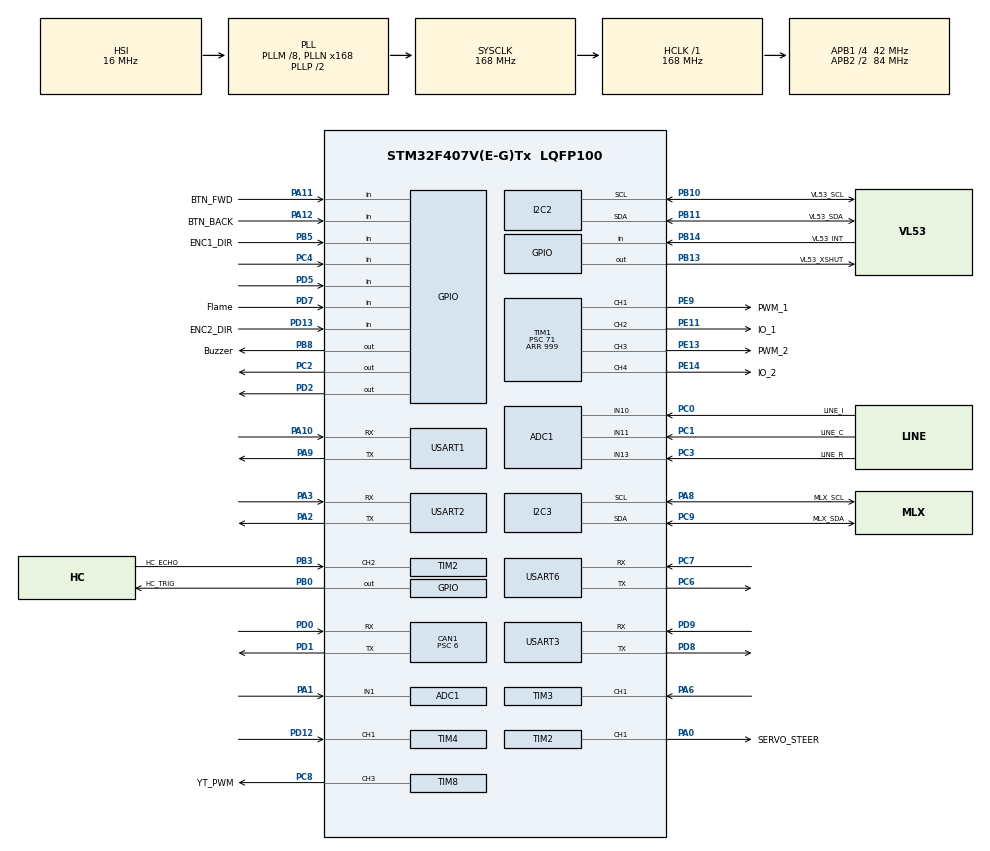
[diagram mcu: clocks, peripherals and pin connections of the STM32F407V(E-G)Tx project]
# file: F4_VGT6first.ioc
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ADC1.Channel-1\#ChannelRegularConversion=ADC_CHANNEL_1
ADC1.Channel-2\#ChannelRegularConversion=ADC_CHANNEL_10
ADC1.Channel-3\#ChannelRegularConversion=ADC_CHANNEL_11
ADC1.Channel-4\#ChannelRegularConversion=ADC_CHANNEL_13
ADC1.ClockPrescaler=ADC_CLOCK_SYNC_PCLK_DIV6
ADC1.ContinuousConvMode=ENABLE
ADC1.NbrOfConversion=4
ADC1.NbrOfConversionFlag=1
ADC1.Rank-1\#ChannelRegularConversion=1
ADC1.Rank-2\#ChannelRegularConversion=2
ADC1.Rank-3\#ChannelRegularConversion=3
ADC1.Rank-4\#ChannelRegularConversion=4
ADC1.SamplingTime-1\#ChannelRegularConversion=ADC_SAMPLETIME_84CYCLES
ADC1.SamplingTime-2\#ChannelRegularConversion=ADC_SAMPLETIME_480CYCLES
ADC1.SamplingTime-3\#ChannelRegularConversion=ADC_SAMPLETIME_480CYCLES
ADC1.SamplingTime-4\#ChannelRegularConversion=ADC_SAMPLETIME_480CYCLES
ADC1.ScanConvMode=ENABLE
ADC1.master=1
CAN1.ABOM=ENABLE
CAN1.BS1=CAN_BS1_11TQ
CAN1.BS2=CAN_BS2_2TQ
CAN1.CalculateBaudRate=500000
CAN1.CalculateTimeBit=2000
CAN1.CalculateTimeQuantum=142.85714285714286
CAN1.NART=ENABLE
CAN1.Prescaler=6
Dma.ADC1.1.Direction=DMA_PERIPH_TO_MEMORY
Dma.ADC1.1.FIFOMode=DMA_FIFOMODE_DISABLE
Dma.ADC1.1.Instance=DMA2_Stream0
Dma.ADC1.1.MemDataAlignment=DMA_MDATAALIGN_HALFWORD
Dma.ADC1.1.MemInc=DMA_MINC_ENABLE
Dma.ADC1.1.Mode=DMA_CIRCULAR
Dma.ADC1.1.PeriphDataAlignment=DMA_PDATAALIGN_HALFWORD
Dma.ADC1.1.PeriphInc=DMA_PINC_DISABLE
Dma.ADC1.1.Priority=DMA_PRIORITY_LOW
Dma.Request0=USART3_TX
Dma.Request1=ADC1
Dma.USART3_TX.0.Direction=DMA_MEMORY_TO_PERIPH
Dma.USART3_TX.0.FIFOMode=DMA_FIFOMODE_DISABLE
Dma.USART3_TX.0.Instance=DMA1_Stream3
Dma.USART3_TX.0.MemDataAlignment=DMA_MDATAALIGN_BYTE
Dma.USART3_TX.0.MemInc=DMA_MINC_ENABLE
Dma.USART3_TX.0.Mode=DMA_NORMAL
Dma.USART3_TX.0.PeriphDataAlignment=DMA_PDATAALIGN_BYTE
Dma.USART3_TX.0.PeriphInc=DMA_PINC_DISABLE
Dma.USART3_TX.0.Priority=DMA_PRIORITY_LOW
FREERTOS.Tasks01=defaultTask,24,128,StartDefaultTask,Default,NULL,Dynamic,NULL,NULL;MotionControlTa,48,256,StartMotionControlTask,Default,NULL,Dynamic,NULL,NULL;ScanTask,32,256,StartScanTask,Default,NULL,Dynamic,NULL,NULL;RangingTask,33,256,Ranging,Default,NULL,Dynamic,NULL,NULL;TelemetryTask,24,256,Telemetry,Default,NULL,Dynamic,NULL,NULL;EnvTask,16,512,Env,Default,NULL,Dynamic,NULL,NULL;ThermalTask,8,1024,Thermal,Default,NULL,Dynamic,NULL,NULL
FREERTOS.configTOTAL_HEAP_SIZE=32768
IWDG.Prescaler=IWDG_PRESCALER_64
IWDG.Reload=2499
Mcu.Family=STM32F4
Mcu.Name=STM32F407V(E-G)Tx
Mcu.Package=LQFP100
NVIC.CAN1_RX0_IRQn=true\:5\:0\:false\:false\:true\:true\:true\:true\:true
NVIC.CAN1_SCE_IRQn=true\:5\:0\:false\:false\:true\:true\:true\:true\:true
NVIC.DMA1_Stream3_IRQn=true\:5\:0\:false\:false\:true\:true\:false\:true\:true
NVIC.DMA2_Stream0_IRQn=true\:5\:0\:false\:false\:true\:true\:false\:true\:true
NVIC.PriorityGroup=NVIC_PRIORITYGROUP_4
NVIC.TIM6_DAC_IRQn=true\:15\:0\:false\:false\:true\:false\:false\:true\:true
NVIC.TimeBase=TIM6_DAC_IRQn
NVIC.TimeBaseIP=TIM6
NVIC.USART3_IRQn=true\:5\:0\:false\:false\:true\:true\:false\:true\:true
PA0-WKUP.GPIO_Label=SERVO_STEER
PA0-WKUP.Signal=S_TIM2_CH1_ETR
PA1.Signal=ADCx_IN1
PA10.Mode=Asynchronous
PA10.Signal=USART1_RX
PA11.GPIO_Label=BTN_FWD
PA11.GPIO_PuPd=GPIO_PULLDOWN
PA11.Signal=GPIO_Input
PA12.GPIO_Label=BTN_BACK
PA12.GPIO_PuPd=GPIO_PULLDOWN
PA12.Signal=GPIO_Input
PA13.Mode=Serial_Wire
PA13.Signal=SYS_JTMS-SWDIO
PA14.Mode=Serial_Wire
PA14.Signal=SYS_JTCK-SWCLK
PA2.Mode=Asynchronous
PA2.Signal=USART2_TX
PA3.Mode=Asynchronous
PA3.Signal=USART2_RX
PA6.Signal=S_TIM3_CH1
PA8.GPIO_Label=MLX_SCL
PA8.GPIO_Pu=GPIO_PULLUP
PA8.Mode=I2C
PA8.Signal=I2C3_SCL
PA9.Mode=Asynchronous
PA9.Signal=USART1_TX
PB0.GPIO_Label=HC_TRIG
PB0.Signal=GPIO_Output
PB10.GPIO_Label=VL53_SCL
PB10.GPIO_Pu=GPIO_PULLUP
PB10.Mode=I2C
PB10.Signal=I2C2_SCL
PB11.GPIO_Label=VL53_SDA
PB11.GPIO_Pu=GPIO_PULLUP
PB11.Mode=I2C
PB11.Signal=I2C2_SDA
PB13.GPIO_Label=VL53_XSHUT
PB13.Signal=GPIO_Output
PB14.GPIO_Label=VL53_INT
PB14.Signal=GPIO_Input
PB3.GPIO_Label=HC_ECHO
PB3.Signal=S_TIM2_CH2
PB5.GPIO_Label=ENC1_DIR
PB5.Signal=GPIO_Input
PB8.GPIO_Label=Buzzer
PB8.GPIO_OutputLevel=GPIO_PIN_SET
PB8.GPIO_PuPd=GPIO_NOPULL
PB8.GPIO_ModeDefaultOutputPP=GPIO_MODE_OUTPUT_OD
PB8.Signal=GPIO_Output
PC0.GPIO_Label=LINE_l
PC0.Signal=ADCx_IN10
PC1.GPIO_Label=LINE_C
PC1.Signal=ADCx_IN11
PC2.Signal=GPIO_Output
PC3.GPIO_Label=LINE_R
PC3.Signal=ADCx_IN13
PC4.Signal=GPIO_Input
PC6.Mode=Asynchronous
PC6.Signal=USART6_TX
PC7.Mode=Asynchronous
PC7.Signal=USART6_RX
PC8.GPIO_Label=YT_PWM
PC8.Signal=S_TIM8_CH3
PC9.GPIO_Label=MLX_SDA
PC9.GPIO_Pu=GPIO_PULLUP
PC9.Mode=I2C
PC9.Signal=I2C3_SDA
PD0.Mode=CAN_Activate
PD0.Signal=CAN1_RX
PD1.Mode=CAN_Activate
PD1.Signal=CAN1_TX
PD12.Signal=S_TIM4_CH1
PD13.GPIO_Label=ENC2_DIR
PD13.Signal=GPIO_Input
PD2.Signal=GPIO_Output
PD5.Signal=GPIO_Input
PD7.GPIO_Label=Flame
PD7.Signal=GPIO_Input
PD8.Mode=Asynchronous
PD8.Signal=USART3_TX
PD9.Mode=Asynchronous
PD9.Signal=USART3_RX
PE11.GPIO_Label=IO_1
PE11.GPIO_Speed=GPIO_SPEED_FREQ_VERY_HIGH
PE11.Signal=S_TIM1_CH2
PE13.GPIO_Label=PWM_2
PE13.GPIO_Speed=GPIO_SPEED_FREQ_VERY_HIGH
PE13.Signal=S_TIM1_CH3
PE14.GPIO_Label=IO_2
PE14.GPIO_Speed=GPIO_SPEED_FREQ_VERY_HIGH
PE14.Signal=S_TIM1_CH4
PE9.GPIO_Label=PWM_1
PE9.GPIO_Speed=GPIO_SPEED_FREQ_VERY_HIGH
PE9.Signal=S_TIM1_CH1
PH0-OSC_IN.Mode=HSE-External-Oscillator
PH0-OSC_IN.Signal=RCC_OSC_IN
PH1-OSC_OUT.Mode=HSE-External-Oscillator
PH1-OSC_OUT.Signal=RCC_OSC_OUT
ProjectManager.HeapSize=0x200
ProjectManager.StackSize=0x400
ProjectManager.TargetToolchain=CMake
RCC.48MHZClocksFreq_Value=84000000
RCC.AHBFreq_Value=168000000
RCC.APB1CLKDivider=RCC_HCLK_DIV4
RCC.APB1Freq_Value=42000000
RCC.APB1TimFreq_Value=84000000
RCC.APB2CLKDivider=RCC_HCLK_DIV2
RCC.APB2Freq_Value=84000000
RCC.APB2TimFreq_Value=168000000
RCC.CortexFreq_Value=168000000
RCC.HCLKFreq_Value=168000000
RCC.HSE_VALUE=25000000
RCC.HSI_VALUE=16000000
RCC.LSE_VALUE=32768
RCC.PLLM=8
RCC.PLLN=168
RCC.SYSCLKFreq_VALUE=168000000
RCC.SYSCLKSource=RCC_SYSCLKSOURCE_PLLCLK
RCC.VCOOutputFreq_Value=336000000
SH.ADCx_IN1.0=ADC1_IN1,IN1
SH.ADCx_IN10.0=ADC1_IN10,IN10
SH.ADCx_IN11.0=ADC1_IN11,IN11
SH.ADCx_IN13.0=ADC1_IN13,IN13
SH.S_TIM1_CH1.0=TIM1_CH1,PWM Generation1 CH1
SH.S_TIM1_CH2.0=TIM1_CH2,PWM Generation2 CH2
SH.S_TIM1_CH3.0=TIM1_CH3,PWM Generation3 CH3
SH.S_TIM1_CH4.0=TIM1_CH4,PWM Generation4 CH4
SH.S_TIM2_CH1_ETR.0=TIM2_CH1,PWM Generation1 CH1
SH.S_TIM2_CH2.0=TIM2_CH2,Input_Capture2_from_TI2
SH.S_TIM3_CH1.0=TIM3_CH1,TriggerSource_TI1FP1
SH.S_TIM4_CH1.0=TIM4_CH1,TriggerSource_TI1FP1
SH.S_TIM8_CH3.0=TIM8_CH3,PWM Generation3 CH3
TIM1.Channel-PWM\ Generation1\ CH1=TIM_CHANNEL_1
TIM1.Channel-PWM\ Generation2\ CH2=TIM_CHANNEL_2
TIM1.Channel-PWM\ Generation3\ CH3=TIM_CHANNEL_3
TIM1.Channel-PWM\ Generation4\ CH4=TIM_CHANNEL_4
TIM1.Period=999
TIM1.Prescaler=71
TIM2.Channel-Input_Capture2_from_TI2=TIM_CHANNEL_2
TIM2.Channel-PWM\ Generation1\ CH1=TIM_CHANNEL_1
TIM2.Period=19999
TIM2.Prescaler=83
TIM3.Slave_TriggerFilter=6
TIM3.TIM_MasterSlaveMode=TIM_MASTERSLAVEMODE_DISABLE
TIM4.Slave_TriggerFilter=6
TIM8.Channel-PWM\ Generation3\ CH3=TIM_CHANNEL_3
TIM8.Period=19999
TIM8.Prescaler=167
TIM8.Pulse-PWM\ Generation3\ CH3=1500
USART1.VirtualMode=VM_ASYNC
USART2.VirtualMode=VM_ASYNC
USART3.VirtualMode=VM_ASYNC
USART6.VirtualMode=VM_ASYNC
VP_FREERTOS_VS_CMSIS_V2.Mode=CMSIS_V2
VP_IWDG_VS_IWDG.Mode=IWDG_Activate
VP_SYS_VS_tim6.Mode=TIM6
VP_TIM3_VS_ControllerModeClock.Mode=Clock Mode
VP_TIM4_VS_ControllerModeClock.Mode=Clock Mode
board=custom

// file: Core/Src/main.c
/* USER CODE BEGIN Header */
/**
  ******************************************************************************
  * @file           : main.c
  * @brief          : Main program body
  ******************************************************************************
  * @attention
  *
  * Copyright (c) 2026 STMicroelectronics.
  * All rights reserved.
  *
  * This software is licensed under terms that can be found in the LICENSE file
  * in the root directory of this software component.
  * If no LICENSE file comes with this software, it is provided AS-IS.
  *
  ******************************************************************************
  */
/* USER CODE END Header */
#include "main.h"
#include "cmsis_os.h"
#include "adc.h"
#include "can.h"
#include "dma.h"
#include "i2c.h"
#include "iwdg.h"
#include "tim.h"
#include "usart.h"
#include "gpio.h"

/* USER CODE BEGIN Includes */
#include <stdio.h>
#include <string.h>
#include <stdarg.h>
#include "watchdog.h"
#include "motor.h"
#include "servo.h"
#include "servo2.h"
#include "encoder.h"
#include "hc.h"
#include "buzzer.h"
#include "mq2.h"
#include "flame.h"
#include "dht11.h"
#include "vl53l0x.h"
#include "linetrack.h"
#include "can_link.h"
/* USER CODE END Includes */

/* USER CODE BEGIN PV */
/* Retain the raw reset flags after RCC clears them, for UART/SWD diagnosis. */
volatile uint32_t g_boot_reset_flags = 0;
/* USER CODE END PV */

void SystemClock_Config(void);
void MX_FREERTOS_Init(void);

/* USER CODE BEGIN 0 */

/**
 * @brief  早期紧急错误输出（直接寄存器操作，不依赖 HAL/外设初始化状态）
 *         在任何阶段都能可靠输出到 USART6 (PC6 TX)。
 */
static void EarlyError_PutChar(char c)
{
    volatile uint32_t delay;
    for (delay = 0; delay < 72000; delay++) {
        if (USART6->SR & USART_SR_TXE) break;
    }
    USART6->DR = (uint8_t)c;
    if (c == '\n') {
        for (delay = 0; delay < 72000; delay++) {
            if (USART6->SR & USART_SR_TXE) break;
        }
        USART6->DR = '\r';
    }
}

static void EarlyError_Print(const char *s)
{
    if (!s) return;
    while (*s) EarlyError_PutChar(*s++);
}

static void EarlyError_Hex32(uint32_t val)
{
    static const char hex[] = "0123456789ABCDEF";
    EarlyError_PutChar('0'); EarlyError_PutChar('x');
    int started = 0;
    for (int i = 28; i >= 0; i -= 4) {
        uint8_t nib = (uint8_t)((val >> i) & 0x0F);
        if (nib || started || i == 0) {
            EarlyError_PutChar(hex[nib]);
            started = 1;
        }
    }
}

static void EarlyError_InitUART6(void)
{
    __HAL_RCC_USART6_CLK_ENABLE();
    __HAL_RCC_GPIOC_CLK_ENABLE();

    GPIO_InitTypeDef gpio = {
        .Pin       = GPIO_PIN_6,
        .Mode      = GPIO_MODE_AF_PP,
        .Pull      = GPIO_NOPULL,
        .Speed     = GPIO_SPEED_FREQ_VERY_HIGH,
        .Alternate = GPIO_AF8_USART6
    };
    HAL_GPIO_Init(GPIOC, &gpio);

    USART6->CR1 = 0;
    USART6->BRR = (uint16_t)((HAL_RCC_GetPCLK2Freq() + 57600) / 115200);
    USART6->CR3 = 0;
    USART6->CR2 = 0;
    USART6->CR1 = USART_CR1_UE | USART_CR1_TE;
}

/* USER CODE END 0 */

int main(void)
{

  /* MCU Configuration--------------------------------------------------------*/

  /* Reset of all peripherals, Initializes the Flash interface and the Systick. */
  HAL_Init();

  /* USER CODE BEGIN Init */
  /* Active-low PB8 must be silent before clock/peripheral initialization. */
  Buzzer_EarlySilence();
  g_boot_reset_flags = RCC->CSR;
  /* USER CODE END Init */

  /* Configure the system clock */
  SystemClock_Config();

  /* Initialize all configured peripherals */
  MX_GPIO_Init();
  MX_DMA_Init();
  MX_TIM1_Init();
  MX_TIM2_Init();
  MX_TIM3_Init();
  MX_TIM4_Init();
  MX_USART2_UART_Init();
  MX_USART3_UART_Init();
  MX_USART6_UART_Init();
  MX_I2C3_Init();
  MX_ADC1_Init();
  MX_I2C2_Init();
  MX_TIM8_Init();
  MX_USART1_UART_Init();
  MX_CAN1_Init();
  MX_IWDG_Init();
  /* USER CODE BEGIN 2 */

  /* 看门狗聚合喂狗：必须在 osKernelStart 之前清标记，否则任务尚未开始打点、
     WDG_Service 一上来就判超时，会在启动阶段直接触发复位。 */
  WDG_Init();

  /* ADC1 四通道 DMA 循环扫描（MQ2 + 3 路 TCRT 模拟量）。
     必须在 MX_DMA_Init() 与 MX_ADC1_Init() 都完成之后启动。 */
  ADC_StartDma();

  /* ---- 故障精确化：分离 Bus/Usage/MemManage 异常(不再一律升级为 HardFault)
     + 关闭默认写缓冲(DISDEFWBUF)让数据总线错误变“精确”(BFAR 给出确切地址)。
     配合 stm32f4xx_it.c 里的 Fault_Report, 崩溃时会从 USART6(PC6) 打印
     CFSR/BFAR/PC, 直接定位非法内存访问。 ---- */
  SCB->SHCSR |= (SCB_SHCSR_BUSFAULTENA_Msk | SCB_SHCSR_USGFAULTENA_Msk | SCB_SHCSR_MEMFAULTENA_Msk);
  SCnSCB->ACTLR |= SCnSCB_ACTLR_DISDEFWBUF_Msk;

  /* ---- 复位原因诊断：定位"启动不正常"根因（欠压/看门狗/软件/按键）----
     BORRST=电源欠压(供电不足) IWDGRST=任务卡死被看门狗复位
     SFTRST=软件复位 PINRST=按键/NRST(正常手动复位) PORRST=正常上电 */
  {
    const char *cause = "UNKNOWN";
    if      (__HAL_RCC_GET_FLAG(RCC_FLAG_IWDGRST)) cause = "IWDG(看门狗复位，需核对任务/故障计数)";
    else if (__HAL_RCC_GET_FLAG(RCC_FLAG_WWDGRST)) cause = "WWDG(窗口看门狗)";
    else if (__HAL_RCC_GET_FLAG(RCC_FLAG_SFTRST))  cause = "SOFT(软件复位)";
    else if (__HAL_RCC_GET_FLAG(RCC_FLAG_PORRST))  cause = "POR/PDR(上电/掉电复位)";
    else if (__HAL_RCC_GET_FLAG(RCC_FLAG_BORRST))  cause = "BOR(电源复位标志，需核对供电)";
    else if (__HAL_RCC_GET_FLAG(RCC_FLAG_PINRST))  cause = "PIN(按键/NRST)";
    LOG("[RESET] flags=0x%08lX cause=%s", (unsigned long)g_boot_reset_flags, cause);
    __HAL_RCC_CLEAR_RESET_FLAGS();
  }

  /* ---- 电机：设载波频率 → 启动 TIM1 四通道 PWM + 使能驱动 ---- */
  /* Motor_Init 把 PWM 载波从 2.33kHz 提到 21kHz（消除啸叫，见 motor.h）。
     必须在 HAL_TIM_PWM_Start 之前设好预分频。 */
  Motor_Init();
  HAL_TIM_PWM_Start(&htim1, TIM_CHANNEL_1);   // Motor1 EN (PE9)
  HAL_TIM_PWM_Start(&htim1, TIM_CHANNEL_2);   // Motor1 PH (PE11)
  HAL_TIM_PWM_Start(&htim1, TIM_CHANNEL_3);   // Motor2 EN (PE13)
  HAL_TIM_PWM_Start(&htim1, TIM_CHANNEL_4);   // Motor2 PH (PE14)
  DRV8701_Enable();                            // 使能电机驱动（外部开关）
  Motor1_Set(0);
  Motor2_Set(0);
  LOG("[BRINGUP] Motors PWM started, DRV8701 enabled, stopped");

  /* ---- 转向舵机 (TIM2_CH1 PA0)，回中 ---- */
  Servo_Init();
  Servo_SetAngle(0);       // 中位
  LOG("[BRINGUP] Steering servo ready, centered (PA0)");

  /* ---- OLED 已移除（2026-07-08 硬件取消，CubeMX 已删 I2C1） ---- */

  /* ---- 编码器 (TIM3 ETR=PA6 / TIM4 ETR=PD12) ---- */
  Encoder_Init();
  LOG("[BRINGUP] Encoders ready (TIM3 PA6 / TIM4 PD12)");

  /* ---- HC-SR04 超声波 (PB0 TRIG / PB3 TIM2_CH2 ECHO) ---- */
  HC_Init();
  LOG("[BRINGUP] HC-SR04 ready (TRIG=PB0, ECHO=TIM2_CH2 PB3)");

  /* ---- 环境/安全传感器 ---- */
  Buzzer_Init();                     // PB8 有源蜂鸣器
  HAL_GPIO_WritePin(ALARM_OUT_GPIO_Port, ALARM_OUT_Pin, GPIO_PIN_RESET);  // PD2 报警联动初始关
  MQ2_Init();                        // PA1(AO)/PC4(DO) 烟雾气体
  Flame_Init();                      // PD7 火焰
  DHT11_Init();                      // PD5 温湿度
  LineTrack_Init();                  // PC0/PC1/PC3 循迹 TCRT×3（GPIO 由 CubeMX 配）
  LOG("[BRINGUP] Env sensors init (MQ2/Flame/DHT11/Buzzer/LineTrack)");
  /* VL53L0X：先总线诊断，再最多 3 次重试初始化（冷启动/上电时序偶发抖动）。
     失败也不阻塞——RangingTask 会在运行时每 2s 自恢复重试(见 Ranging())。 */
  uint8_t vl_id = 0;
  uint8_t vl_probe = VL53_BusProbe(&vl_id);
  int vl = -99;
  for (int attempt = 0; attempt < 3; attempt++) {
    vl = VL53_Init();
    if (vl == 0) break;
    HAL_Delay(20);
  }
  if (vl == 0) {
    LOG("[BRINGUP] VL53L0X ready (I2C2, cont.)  probe=%u id=0x%02X", vl_probe, vl_id);
  } else if (vl_probe == 0) {
    LOG("[BRINGUP] VL53L0X FAIL: 总线无ACK(id=0x%02X) -> 查 PB10=SCL/PB11=SDA/PB13=XSHUT/3.3V/上拉。运行时会自恢复", vl_id);
  } else {
    LOG("[BRINGUP] VL53L0X FAIL: init=%d probe=%u id=0x%02X(应0xEE) -> 芯片应答但初始化未过。运行时会自恢复", vl, vl_probe, vl_id);
  }
  /* VL53 失败 → 扫 I2C2 总线一锤定音：
     0 器件应答 = 总线级问题(上拉缺失/未供电/SDA-SCL接反/未共地/XSHUT压低)；
     有器件 = 芯片在线(0x29=VL53默认)，问题在地址/初始化。 */
  if (vl != 0) {
    int i2c_found = 0;
    for (uint8_t a = 0x08; a <= 0x77; a++) {
      if (HAL_I2C_IsDeviceReady(&hi2c2, (uint16_t)(a << 1), 1, 3) == HAL_OK) {
        LOG("[I2C2] device ACK @0x%02X (7-bit)", a);
        i2c_found++;
      }
    }
    if (i2c_found == 0)
      LOG("[I2C2] 总线全哑: 0 器件应答 -> 上拉缺失 / 未供3.3V / SDA-SCL接反 / 未共地");
    else
      LOG("[I2C2] 共 %d 器件应答 (VL53 默认 7-bit 0x29)", i2c_found);
  }

  /* ---- 云台舵机 Servo2 (PB1, TIM2 中断硬件定时 PWM)，回中 ---- */
  Servo2_Init();
  Servo2_SetPulse(SERVO2_MID);  // 云台回中（非阻塞，脉冲由 TIM2 中断持续生成）
  LOG("[BRINGUP] Pan servo (Servo2) ready, centered (PB1)");

  /* ---- CAN 链路（500kbps，CANopen Node 1，见实施方案 §3）----
     CubeMX 只建外设(MX_CAN1_Init)；过滤器/启动/中断通知须手写，缺了收不到任何帧。
     只放行 0x201 命令 / 0x301 巡检避障 / 0x601 SDO；上行遥测走 0x181/0x281/0x381/0x701。
     USART3 保留为回退链路（LINK_USE_CAN 开关，见 freertos.c）。 */
  CANLink_Init();
#if CAN_LOOPBACK_TEST
  LOG("========================================================");
  LOG("  !!! CAN SILENT-LOOPBACK SELF-TEST MODE (P1) !!!");
  LOG("  TX internally looped to RX; CANTX pin held recessive.");
  LOG("  NOT on the real bus -- PCAN will see NOTHING. Expected.");
  LOG("  PASS = [CAN] tx+ rxoth+ err=0 boff=0 TEC=0 REC=0 LEC=NoErr");
  LOG("  -> then set CAN_LOOPBACK_TEST=0 in can_link.h and reflash!");
  LOG("========================================================");
#else
  LOG("[BRINGUP] CAN1 up @500kbps (RX:0x201/0x301/0x601  TX:0x181/0x281/0x381/0x701)");
#endif

  /* 固件版本横幅：烧录后看这行即可确认跑的是不是最新固件（含各修复） */
  LOG("[FW] F4 v1.25.5: active-low PB8 open-drain silence; corrected line sensor L/R");

  LOG("[BRINGUP] All peripherals OK -> starting FreeRTOS scheduler");
  LOG("[INFO] Startup holds servos centered; bench self-checks are disabled by default");
  LOG("[INFO]   PA11 = Forward, PA12 = Backward (active-low)");

  /* USER CODE END 2 */

  /* Init scheduler */
  osKernelInitialize();  /* Call init function for freertos objects (in cmsis_os2.c) */
  MX_FREERTOS_Init();

  /* Start scheduler */
  osKernelStart();

  /* We should never get here as control is now taken by the scheduler */

  /* Infinite loop */
  while (1)
  {

  }
}

void SystemClock_Config(void)
{
  RCC_OscInitTypeDef RCC_OscInitStruct = {0};
  RCC_ClkInitTypeDef RCC_ClkInitStruct = {0};

  /** Configure the main internal regulator output voltage
  */
  __HAL_RCC_PWR_CLK_ENABLE();
  __HAL_PWR_VOLTAGESCALING_CONFIG(PWR_REGULATOR_VOLTAGE_SCALE1);

  /** Initializes the RCC Oscillators according to the specified parameters
  * in the RCC_OscInitTypeDef structure.
  */
  RCC_OscInitStruct.OscillatorType = RCC_OSCILLATORTYPE_HSI|RCC_OSCILLATORTYPE_LSI;
  RCC_OscInitStruct.HSIState = RCC_HSI_ON;
  RCC_OscInitStruct.HSICalibrationValue = RCC_HSICALIBRATION_DEFAULT;
  RCC_OscInitStruct.LSIState = RCC_LSI_ON;
  RCC_OscInitStruct.PLL.PLLState = RCC_PLL_ON;
  RCC_OscInitStruct.PLL.PLLSource = RCC_PLLSOURCE_HSI;
  RCC_OscInitStruct.PLL.PLLM = 8;
  RCC_OscInitStruct.PLL.PLLN = 168;
  RCC_OscInitStruct.PLL.PLLP = RCC_PLLP_DIV2;
  RCC_OscInitStruct.PLL.PLLQ = 4;
  if (HAL_RCC_OscConfig(&RCC_OscInitStruct) != HAL_OK)
  {
    Error_Handler();
  }

  /** Initializes the CPU, AHB and APB buses clocks
  */
  RCC_ClkInitStruct.ClockType = RCC_CLOCKTYPE_HCLK|RCC_CLOCKTYPE_SYSCLK
                              |RCC_CLOCKTYPE_PCLK1|RCC_CLOCKTYPE_PCLK2;
  RCC_ClkInitStruct.SYSCLKSource = RCC_SYSCLKSOURCE_PLLCLK;
  RCC_ClkInitStruct.AHBCLKDivider = RCC_SYSCLK_DIV1;
  RCC_ClkInitStruct.APB1CLKDivider = RCC_HCLK_DIV4;
  RCC_ClkInitStruct.APB2CLKDivider = RCC_HCLK_DIV2;

  if (HAL_RCC_ClockConfig(&RCC_ClkInitStruct, FLASH_LATENCY_5) != HAL_OK)
  {
    Error_Handler();
  }
}

/* USER CODE BEGIN 4 */

/**
 * @brief  printf() 重定向到 USART6 (PC6 TX)
 *         这样 printf() 输出可以从调试串口看到。
 */
int __io_putchar(int ch)
{
    /* 如果在 USART6 初始化完成前调用，则不输出 */
    if (huart6.Instance == USART6 && (USART6->CR1 & USART_CR1_UE))
    {
        /* 轮询等待 TXE，然后写入 DR */
        while (!(USART6->SR & USART_SR_TXE));
        USART6->DR = (uint8_t)(ch & 0xFF);
    }
    return ch;
}

/**
 * @brief  printf 风格日志输出到 USART6 (PC6 TX)，供 main.h 的 LOG() 宏调用。
 *         FreeRTOS 任务通过 LOG() → UART_Log() 输出调试信息到独立调试串口，
 *         不占用 USART3（蓝牙遥控数据帧通道）。
 */
void UART_Log(const char *format, ...)
{
    char buffer[128];
    va_list args;
    va_start(args, format);
    int len = vsnprintf(buffer, sizeof(buffer), format, args);
    va_end(args);
    /* ★关键：vsnprintf 返回的是“未截断时的完整长度”，可能 > sizeof(buffer)。
       必须夹取到实际写入缓冲区的字节数，否则 HAL_UART_Transmit 会越界读取
       buffer 之后的栈内存——当日志行超过 128B 时会一路读到 RAM 顶 0x20020000
       触发精确总线错误(PRECISERR)。夹到 sizeof-1(截断后有效字符数)。 */
    if (len > (int)sizeof(buffer) - 1) len = (int)sizeof(buffer) - 1;
    if (len > 0)
    {
        /* 有限超时(20ms)：即使 USART6/PC6 调试口异常也不会把启动/任务冻死。
           128B @115200 约 11ms，20ms 留足余量；超时则丢弃本行、继续运行。 */
        HAL_UART_Transmit(&huart6, (uint8_t *)buffer, (uint16_t)len, 20);
    }
}

/**
 * @brief  FreeRTOS configASSERT 调用此函数输出诊断信息
 */
void vAssertCalled(const char *file, int line)
{
    /* 直接写 USART6 寄存器（不依赖 HAL/OS） */
    if (USART6->CR1 & USART_CR1_UE)
    {
        const char *p;
        p = "\r\n!!! RTOS ASSERT: ";
        while (*p) { while(!(USART6->SR & USART_SR_TXE)); USART6->DR = *p++; }
        while (*file) { while(!(USART6->SR & USART_SR_TXE)); USART6->DR = *file++; }
        /* 冒号 + 行号 */
        char tmp[16];
        int n = snprintf(tmp, sizeof(tmp), ":%d !!!\r\n", line);
        for (int i = 0; i < n && i < 16; i++) {
            while(!(USART6->SR & USART_SR_TXE));
            USART6->DR = (uint8_t)tmp[i];
        }
    }
}

/* USER CODE END 4 */

void HAL_TIM_PeriodElapsedCallback(TIM_HandleTypeDef *htim)
{
  if (htim->Instance == TIM6)
  {
    HAL_IncTick();
  }
}

void Error_Handler(void)
{
  /* USER CODE BEGIN Error_Handler_Debug */

  /* 第一步：使能 USART6 并输出（总是尝试，即使此时外设尚未初始化） */
  EarlyError_InitUART6();
  EarlyError_Print("\r\n");
  EarlyError_Print("!!!!!!!!!!!!!!!!!!!!!!!!!!!\r\n");
  EarlyError_Print("  ERROR HANDLER TRIGGERED\r\n");
  EarlyError_Print("  CR1="); EarlyError_Hex32(USART6->CR1);
  EarlyError_Print("  SR=");  EarlyError_Hex32(USART6->SR);
  EarlyError_Print("\r\n  USART3: CR1="); EarlyError_Hex32(USART3->CR1);
  EarlyError_Print("  SR=");  EarlyError_Hex32(USART3->SR);
  EarlyError_Print("\r\n!!!!!!!!!!!!!!!!!!!!!!!!!!!\r\n");

  __disable_irq();
  while (1)
  {
  }
  /* USER CODE END Error_Handler_Debug */
}
#ifdef USE_FULL_ASSERT
/**
  * @brief  Reports the name of the source file and the source line number
  *         where the assert_param error has occurred.
  * @param  file: pointer to the source file name
  * @param  line: assert_param error line source number
  * @retval None
  */
void assert_failed(uint8_t *file, uint32_t line)
{
  /* USER CODE BEGIN 6 */
  EarlyError_InitUART6();
  EarlyError_Print("\r\n!!! ASSERT FAILED: ");
  EarlyError_Print((const char*)file);
  EarlyError_PutChar(':');
  /* 手动输出行号 */
  uint32_t n = line;
  char rev[12]; int ri = 0;
  do { rev[ri++] = '0' + (n % 10); n /= 10; } while (n);
  while (ri > 0) EarlyError_PutChar(rev[--ri]);
  EarlyError_Print(" !!!\r\n");
  __disable_irq();
  while (1);
  /* USER CODE END 6 */
}
#endif /* USE_FULL_ASSERT */

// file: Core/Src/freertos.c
/* USER CODE BEGIN Header */
/**
  ******************************************************************************
  * File Name          : freertos.c
  * Description        : Code for freertos applications
  ******************************************************************************
  * @attention
  *
  * Copyright (c) 2026 STMicroelectronics.
  * All rights reserved.
  *
  * This software is licensed under terms that can be found in the LICENSE file
  * in the root directory of this software component.
  * If no LICENSE file comes with this software, it is provided AS-IS.
  *
  ******************************************************************************
  */
/* USER CODE END Header */

#include "FreeRTOS.h"
#include "task.h"
#include "main.h"
#include "cmsis_os.h"

/* USER CODE BEGIN Includes */
#include "servo.h"
#include "servo2.h"
#include "motor.h"
#include "motion_control.h"
#include "encoder.h"
#include "hc.h"
#include "protocol.h"
#include "stdio.h"
#include "string.h"
#include "tim.h"
#include "usart.h"
#include "bt_debug.h"
#include "boot_trace.h"
#include "thermal.h"
#include "buzzer.h"
#include "mq2.h"
#include "flame.h"
#include "dht11.h"
#include "vl53l0x.h"
#include "linetrack.h"
#include "patrol.h"
#include "runtime_control.h"
#include "watchdog.h"
#include "i2c_recover.h"
#include "pid.h"
#include "can_link.h"
/* USER CODE END Includes */

/* USER CODE BEGIN PTD */

/* ============================================================================
 *  任务分层（2026-07-08 重构，对应《深度优化报告》方案A + CubeMX 任务表）：
 *    MotionControlTa (Realtime,   17ms) 运动闭环：遥控解析/差速/PID/测试激励
 *    RangingTask     (AboveNorm1,  1ms) 测距采集：HC 状态机推进 + VL53 非阻塞读
 *    ScanTask        (AboveNormal)      云台默认居中保持；全行程自检仅限台架
 *    TelemetryTask   (Normal,     20ms) 上报专职：7B 遥测 + 扩展帧 + PID 遥测
 *    EnvTask         (BelowNormal,100ms)慢速环境：MQ2/火焰/DHT11/蜂鸣 + 0x5C
 *    ThermalTask     (Low,        200ms)热成像原始帧转发（USART1 专线）
 *  原则：采集/决策/上报分离；阻塞大户(DHT11/热成像TX)下沉低优先级；
 *        Encoder_Update 仅 MotionControlTask 调用（修双任务竞态）；
 *        OLED 已移除（硬件取消，2026-07-08）。
 * ==========================================================================*/

/* 平滑过渡速度档位 */
#define RAMP_REMOTE_STEP    SERVO_RAMP_FAST_STEP   // 遥控模式：步长上限，比例步长自动减速收尾
#define RAMP_SWITCH_STEP    8                       // 模式切换：中速步长上限

/* ===== 遥控避障锁（2026-07-23）=========================================
 *  遥控时操作不当容易撞前方障碍。加一道硬锁：前方过近立即停止前进，
 *  且【不会因为障碍移开就自动放行】，必须操作者二次确认才解锁，
 *  避免"贴着障碍物继续推摇杆"这种最危险的情形。
 *
 *  触发：前方有效距离 <= OBS_LOCK_ON_MM（8cm）
 *  解锁：障碍已退到 OBS_LOCK_OFF_MM（12cm，迟滞防抖）之外，
 *        且操作者连续给出 OBS_UNLOCK_NEED 次【新的前进意图】。
 *        "新的前进意图" = speed 从 <=0 跳变到 >0 的上升沿 —— 之所以用边沿
 *        而不是数帧，是因为龙芯 30Hz 持续下发命令帧（兼心跳），
 *        按帧数算 2 帧只要 66ms，锁形同虚设；用边沿则要求操作者
 *        真的松手再推两次，才是有意义的"二次确认"。
 *  锁定期间：前进(speed>0)一律置 0；后退(speed<0)放行，便于倒车脱困。 */
#define OBS_LOCK_ON_MM       80U    /* 8cm：进入锁定 */
#define OBS_LOCK_OFF_MM     120U    /* 12cm：迟滞解除阈值，防止在阈值附近反复抖动 */
#define OBS_UNLOCK_NEED       2U    /* 需要的前进意图边沿次数 */
#define OBS_UNLOCK_WINDOW_MS 5000U  /* 两次意图的最大间隔，超时清零重新计数 */

/* ★ 2026-07-23 实测修正：触发锁必须连续确认，且优先信任激光。
 *   现象：行进中超声波读数剧烈跳变（85cm→17cm→9cm→85cm），同期 VL53 稳定 867mm。
 *   根因：HC-SR04 锥角宽(±15°)，车一动就打到地面/侧物产生假回波，叠加电机 EMI。
 *   原实现取 min(VL53,HC) 且【单次读数即触发】，正好被这些毛刺打中 ——
 *   一跳到 9cm 就锁死前进，操作者推两次解锁后又被下一个毛刺锁上，
 *   表现为行进中反复顿挫，也就是用户反馈的"卡顿"。
 *   现策略：
 *     1) VL53 有效时【以 VL53 为准】—— 窄视场、抗 EMI、毫米级精度；
 *        仅当 VL53 超量程(前方 1.2m 内无目标)时才回退到超声波。
 *     2) 无论用哪个源，都要连续 OBS_CONFIRM_N 次判近才真正锁定，单次毛刺不算数。 */
#define OBS_CONFIRM_N         3U    /* 连续确认次数（17ms/次 → 约 51ms 才锁） */

/* 云台开机建图扫描步长(us/10ms循环)：全行程 2000us / 8 ≈ 2.5s 单程 */
#define SWEEP2_STEP         8

/* USER CODE END PTD */

/* USER CODE BEGIN PD */

/* Heartbeat deadlines use elapsed RTOS milliseconds, not loop counts. */
#define HB_ACTIVE_MAX 85U
#define HB_HOLD_MAX 510U

/* Full-travel boot tests are bench-only: do not load both servos at power-on. */
#ifndef BOOT_SERVO_SELF_TEST_ENABLED
#define BOOT_SERVO_SELF_TEST_ENABLED 0
#endif
#ifndef BOOT_PAN_SCAN_ENABLED
#define BOOT_PAN_SCAN_ENABLED 0
#endif

#ifndef THERMAL_TASK_ENABLED
#define THERMAL_TASK_ENABLED 1     /* MLX90640 原始帧转发（USART1 专线） */
#endif

/* ★ CAN 链路开关（实施方案 §3.6.6）：1=上行遥测/心跳同时走 CAN（与 USART3 并行，
   便于 A/B 对比与 candump 验证）；0=仅 USART3。命令 RX 两条链路始终都收，
   谁连着谁生效（见 can_link.c 的 0x201 分发与 usart.c 的 ISR）。 */
#ifndef LINK_USE_CAN
#define LINK_USE_CAN 1
#endif

/* CPS controller parameters are defined in motion_control.c. */
#define PID_TUNING_ENABLED   0

/* USER CODE END PD */

/* USER CODE BEGIN Variables */

/* USART3 发送互斥锁：TelemetryTask / EnvTask 共用同一 TX，
   用带优先级继承的互斥锁串行化，避免帧交错损坏。 */
osMutexId_t g_usart3_mtx = NULL;
static const osMutexAttr_t usart3_mtx_attr = {
  .name = "usart3Tx",
  .attr_bits = osMutexPrioInherit,
};

/* 加锁发送一帧到 USART3（互斥锁未建成时退化为直接发送） */
static void USART3_SendFrameSync(const uint8_t *f, uint8_t len)
{
  if (g_usart3_mtx) osMutexAcquire(g_usart3_mtx, osWaitForever);
  USART3_SendFrame(f, len);
  if (g_usart3_mtx) osMutexRelease(g_usart3_mtx);
}

/* USART6 debug port (COM26 on the bench): accept the same binary control/PID
   frames as USART3 so PID can be tuned directly through the local USB-serial
   adapter, without Loongson/LongLook in the loop. */
#define DBG_RX_STATE_IDLE 0U
#define DBG_RX_STATE_RECV 1U
static uint8_t dbg_rx_state = DBG_RX_STATE_IDLE;
static uint8_t dbg_rx_frame[FRAME_PIDPARAM_LENGTH];
static uint8_t dbg_rx_idx = 0;
static uint8_t dbg_rx_expect = FRAME_LENGTH;

static void DebugUart_ProcessRxByte(uint8_t byte)
{
    static uint32_t lastByteMs=0;
    uint32_t now=HAL_GetTick();
    if(now-lastByteMs>50U) { dbg_rx_state=0; dbg_rx_idx=0; }
    lastByteMs=now;
  switch (dbg_rx_state)
  {
  case DBG_RX_STATE_IDLE:
    if (byte == FRAME_HEADER)
    {
      dbg_rx_frame[0] = byte;
      dbg_rx_idx = 1;
      dbg_rx_expect = FRAME_LENGTH;
      dbg_rx_state = DBG_RX_STATE_RECV;
    }
    break;

  case DBG_RX_STATE_RECV:
    if (dbg_rx_idx == 1U)
    {
      if      (byte == 0x63U) dbg_rx_expect = 12U;
      else if (byte == FRAME_PIDPARAM_MARKER) dbg_rx_expect = FRAME_PIDPARAM_LENGTH;
      else if (byte == FRAME_PIDTEST_MARKER)  dbg_rx_expect = FRAME_PIDTEST_LENGTH;
      else                                    dbg_rx_expect = FRAME_LENGTH;
    }
/* A payload byte 0xAA is legal (e.g. speed=170); only inter-byte timeout resynchronizes. */
    dbg_rx_frame[dbg_rx_idx++] = byte;
    if (dbg_rx_idx >= dbg_rx_expect)
    {
      uint8_t raw[FRAME_PIDPARAM_LENGTH];
      for (uint8_t i = 0; i < dbg_rx_expect; ++i) raw[i] = dbg_rx_frame[i];

      if (dbg_rx_expect == 12U) { Runtime_UartRequest(raw); }
      else if (dbg_rx_expect == FRAME_PIDPARAM_LENGTH)
      {
#if PID_TUNING_ENABLED
        if (Protocol_CalculateChecksum(raw, FRAME_PIDPARAM_LENGTH - 1U) == raw[FRAME_PIDPARAM_LENGTH - 1U] &&
            Protocol_UnpackPidParam(raw, &g_pid_param_rx))
        {
          g_pid_param_ready = 1;
          g_rx_pid_frame_cnt++;
          LOG("[DDBG] PID param frame accepted via USART6");
        }
        else g_rx_crc_err++;
#endif
      }
      else if (dbg_rx_expect == FRAME_PIDTEST_LENGTH)
      {
#if PID_TUNING_ENABLED
        if (Protocol_CalculateChecksum(raw, FRAME_PIDTEST_LENGTH - 1U) == raw[FRAME_PIDTEST_LENGTH - 1U] &&
            Protocol_UnpackPidTest(raw, &g_pid_test_rx))
        {
          g_pid_test_ready = 1;
          g_rx_pid_frame_cnt++;
          LOG("[DDBG] PID test frame accepted via USART6");
        }
        else g_rx_crc_err++;
#endif
      }
      else if ((raw[5] & TELEMETRY_FLAG) == 0U)
      {
        ControlData tmp;
        if (Protocol_UnpackCommandFrame(raw, &tmp))
        {
          g_remote_data = tmp;
          g_remote_ready = 1;
          g_rx_frame_cnt++;
          LOG("[DDBG] cmd via USART6 spd=%d steer=%d mode=%u", tmp.speed, tmp.steering, tmp.mode);
        }
        else g_rx_crc_err++;
      }

      dbg_rx_state = DBG_RX_STATE_IDLE;
      dbg_rx_idx = 0;
    }
    break;
  }
}

static void DebugUart_PollRx(void)
{
  while (__HAL_UART_GET_FLAG(&huart6, UART_FLAG_RXNE))
  {
    DebugUart_ProcessRxByte((uint8_t)(huart6.Instance->DR & 0xFFU));
  }
  if (__HAL_UART_GET_FLAG(&huart6, UART_FLAG_ORE))
  {
    __HAL_UART_CLEAR_OREFLAG(&huart6);
    dbg_rx_state = DBG_RX_STATE_IDLE;
    dbg_rx_idx = 0;
  }
}

/* 链路激活标志：由 MotionControlTask 维护（1=SBC/手柄已连接）。
   Telemetry/Env/Thermal 据此决定是否上报，避免链路空闲时占满 USART3。 */
volatile uint8_t g_remote_active = 0;

/* ---- RangingTask 发布的激光测距（EnvTask/运动决策消费，32 位读写在 M4 上原子） ---- */
volatile uint16_t g_vl53_mm      = VL53_OUT_OF_RANGE;
volatile uint32_t g_vl53_ok_cnt  = 0;    /* 有效样本计数（诊断链路活性） */
volatile uint8_t  g_line_bits    = 0;    /* 循迹位域(L/C/R/junction/lost)，RangingTask 发布 */
volatile uint8_t  g_obs_lock     = 0;    /* 遥控避障锁状态，MotionControlTask 发布，EnvTask 上报 */

/* ---- 巡检事件/状态（MotionControlTask 产生 → TelemetryTask 经 CAN 0x481 上报）---- */
volatile uint8_t  g_patrol_state     = 0;   /* PatrolStateT */
volatile uint8_t  g_patrol_event     = 0;   /* PatrolEventT，待上报 */
volatile uint8_t  g_patrol_point_seq = 0;   /* 路口计数 */
volatile uint8_t  g_patrol_evt_ready = 0;   /* 1=有新事件待发 */

/* ---- MotionControlTask 发布的运动快照（TelemetryTask 消费） ---- */
volatile int16_t g_mot_speed      = 0;   /* 当前命令速度 */
volatile int16_t g_mot_steer_tele = 0;   /* 舵机回读转向(-1000~1000) */
volatile uint8_t g_mot_mode       = MODE_MANUAL;

/* Read-only controller snapshot: Motor1=left/ENC2, Motor2=right/ENC1; CPS. */
volatile uint8_t g_pt_flags = 0;   /* bit0=closed-loop, bit2=motion fault */
volatile int16_t g_pt_targL = 0, g_pt_measL = 0, g_pt_outL = 0;
volatile int16_t g_pt_targR = 0, g_pt_measR = 0, g_pt_outR = 0;
volatile uint8_t g_motion_fault = 0;
volatile uint32_t g_motion_dt_us = 17000;

/* USER CODE END Variables */
/* Definitions for defaultTask */
osThreadId_t defaultTaskHandle;
const osThreadAttr_t defaultTask_attributes = {
  .name = "defaultTask",
  .stack_size = 128 * 4,
  .priority = (osPriority_t) osPriorityNormal,
};
/* Definitions for MotionControlTa */
osThreadId_t MotionControlTaHandle;
const osThreadAttr_t MotionControlTa_attributes = {
  .name = "MotionControlTa",
  .stack_size = 384 * 4,
  .priority = (osPriority_t) osPriorityRealtime,
};
/* Definitions for ScanTask */
osThreadId_t ScanTaskHandle;
const osThreadAttr_t ScanTask_attributes = {
  .name = "ScanTask",
  .stack_size = 256 * 4,
  .priority = (osPriority_t) osPriorityAboveNormal,
};
/* Definitions for RangingTask */
osThreadId_t RangingTaskHandle;
const osThreadAttr_t RangingTask_attributes = {
  .name = "RangingTask",
  .stack_size = 256 * 4,
  .priority = (osPriority_t) osPriorityAboveNormal1,
};
/* Definitions for TelemetryTask */
osThreadId_t TelemetryTaskHandle;
const osThreadAttr_t TelemetryTask_attributes = {
  .name = "TelemetryTask",
  .stack_size = 256 * 4,
  .priority = (osPriority_t) osPriorityNormal,
};
/* Definitions for EnvTask */
osThreadId_t EnvTaskHandle;
const osThreadAttr_t EnvTask_attributes = {
  .name = "EnvTask",
  .stack_size = 512 * 4,
  .priority = (osPriority_t) osPriorityBelowNormal,
};
/* Definitions for ThermalTask */
osThreadId_t ThermalTaskHandle;
const osThreadAttr_t ThermalTask_attributes = {
  .name = "ThermalTask",
  .stack_size = 1024 * 4,
  .priority = (osPriority_t) osPriorityLow,
};

void StartDefaultTask(void *argument);
void StartMotionControlTask(void *argument);
void StartScanTask(void *argument);
void Ranging(void *argument);
void Telemetry(void *argument);
void Env(void *argument);
void Thermal(void *argument);

void MX_FREERTOS_Init(void); /* (MISRA C 2004 rule 8.1) */

void MX_FREERTOS_Init(void) {

  /* USER CODE BEGIN RTOS_MUTEX */
  g_usart3_mtx = osMutexNew(&usart3_mtx_attr);
  /* USER CODE END RTOS_MUTEX */

  /* Create the thread(s) */
  /* creation of defaultTask */
  defaultTaskHandle = osThreadNew(StartDefaultTask, NULL, &defaultTask_attributes);

  /* creation of MotionControlTa */
  MotionControlTaHandle = osThreadNew(StartMotionControlTask, NULL, &MotionControlTa_attributes);

  /* creation of ScanTask */
  ScanTaskHandle = osThreadNew(StartScanTask, NULL, &ScanTask_attributes);

  /* creation of RangingTask */
  RangingTaskHandle = osThreadNew(Ranging, NULL, &RangingTask_attributes);

  /* creation of TelemetryTask */
  TelemetryTaskHandle = osThreadNew(Telemetry, NULL, &TelemetryTask_attributes);

  /* creation of EnvTask */
  EnvTaskHandle = osThreadNew(Env, NULL, &EnvTask_attributes);

  /* creation of ThermalTask */
  ThermalTaskHandle = osThreadNew(Thermal, NULL, &ThermalTask_attributes);

  /* USER CODE BEGIN RTOS_THREADS */
  /* 旧 EnvSensorTask/ThermalTask(USER CODE 版) 已迁入 CubeMX 任务表的
     EnvTask/ThermalTask（上方生成区创建），此处不再重复创建。 */
  /* USER CODE END RTOS_THREADS */

}

void StartDefaultTask(void *argument)
{
  /* USER CODE BEGIN StartDefaultTask */
  /* 独立蜂鸣器快速节拍：环境任务含 DHT11 阻塞读，不能承担报警节奏。 */
  for(;;)
  {
    Buzzer_Tick(20U);
    osDelay(20U);
  }
  /* USER CODE END StartDefaultTask */
}

void StartMotionControlTask(void *argument)
{
  /* USER CODE BEGIN StartMotionControlTask */
  DUART_Trace("MotionControlTask started (Realtime priority)");

  // 启动 USART3 接收中断
  MX_USART3_StartRx();
  BTDbg_Init();
  LOG("[TASK] MotionControlTask started (Realtime). Steering self-check begins.");

  #define MOTOR_TEST_SPEED  500

  int16_t current_speed = 0;
  uint8_t current_mode = MODE_MANUAL;

  // 心跳超时跟踪
  uint32_t s_remote_tick = 0;
  uint8_t  remote_active  = 0;           // 0=纯本地模式, 1=遥控已激活

  // 差速转向：保存从遥控帧中解析的原始转向值 (-1000~+1000)
  int16_t s_raw_steering  = 0;
  int16_t s_last_left_spd  = 0;
  int16_t s_last_right_spd = 0;

  // 遥控避障锁状态（见文件头 OBS_LOCK_* 宏说明）
  uint8_t  s_obs_lock       = 0;   /* 1=锁定中，前进被强制归零 */
  uint8_t  s_obs_near_cnt   = 0;   /* 连续判近次数，达 OBS_CONFIRM_N 才锁（抗毛刺） */
  uint8_t  s_obs_unlock_cnt = 0;   /* 已累计的前进意图边沿次数 */
  uint32_t s_obs_last_intent_ms = 0; /* 最近一次前进意图时刻，用于超时清零 */
  int16_t  s_obs_prev_cmd_spd = 0; /* 上一帧遥控速度，用于检测 <=0 -> >0 上升沿 */

  // 舵机自检状态机：0=INIT,1=→LEFT,2=WAIT_L,3=→RIGHT,4=WAIT_R,5=→CENTER,6=DONE
  uint8_t  sc_state = BOOT_SERVO_SELF_TEST_ENABLED ? 0U : 6U;
  uint8_t  sc_wait  = 0;

  MotionControl motion; Motion_Init(&motion);
  uint32_t sampleCycles = 0, controlDeadline = osKernelGetTickCount();
  uint8_t previousMode = MODE_MANUAL;
  int8_t   last_btn_cmd = 0;

  for(;;)
  {
    // ===== 0. 看门狗：本任务打存活点 + 聚合校验后喂狗（唯一喂狗点） =====
    /* 改造前是无条件 IWDG->KR=0xAAAA，只能发现整块 MCU 死掉；
       现由 WDG_Service 校验【所有】受监护任务都在截止期内打过点才喂狗，
       任一任务卡死或数据异常累计超限即停止喂狗，约 5s 后 IWDG 复位。 */
    WDG_Kick(WDG_TASK_MOTION);
    WDG_Service();

    // ===== 显式启用的台架自检阶段（默认关闭；期间不动驱动电机） =====
    if (sc_state < 6)
    {
      uint8_t arrived = (Servo_RampTick() == 0);
      switch (sc_state)
      {
      case 0:
        Servo_SetSmoothAngle(SERVO_ANGLE_MAX, SERVO_RAMP_FAST_STEP);
        LOG("[SELF-CHECK 1/3] Steering -> LEFT  +%d deg", SERVO_ANGLE_MAX);
        sc_state = 1;
        break;
      case 1:
        if (arrived) { sc_wait = 8; sc_state = 2; }
        break;
      case 2:
        if (--sc_wait == 0) {
          Servo_SetSmoothAngle(SERVO_ANGLE_MIN, SERVO_RAMP_FAST_STEP);
          LOG("[SELF-CHECK 2/3] Steering -> RIGHT %d deg", SERVO_ANGLE_MIN);
          sc_state = 3;
        }
        break;
      case 3:
        if (arrived) { sc_wait = 8; sc_state = 4; }
        break;
      case 4:
        if (--sc_wait == 0) {
          Servo_SetSmoothAngle(0, SERVO_RAMP_FAST_STEP);
          LOG("[SELF-CHECK 3/3] Steering -> CENTER (reset)");
          sc_state = 5;
        }
        break;
      case 5:
        if (arrived) {
          sc_state = 6;
          LOG("[SELF-CHECK] DONE. Steering centered, pulse=%u us", Servo_GetCurrentPulse());
          LOG("[READY] Buttons: PA11=Forward PA12=Backward. Ctrl RX on USART3.");
        }
        break;
      }
      osDelay(17);
      continue;
    }

    // ===== 正常控制阶段 ============================================

    Servo_RampTick();
    DebugUart_PollRx();
    USART3_PollRx();
    USART3_EnsureRxActive();
    uint8_t operator_update = 0;
    int16_t operator_speed = 0;

    // ===== 1. 遥控数据消费（优先级高于本地按键） =====
    if (g_remote_ready)
    {
      taskENTER_CRITICAL();
      ControlData remote = g_remote_data;
      g_remote_ready = 0;
      taskEXIT_CRITICAL();

      s_remote_tick = osKernelGetTickCount();
      remote_active = 1;

      current_speed = remote.speed;
      operator_speed = remote.speed;
      operator_update = 1;
      current_mode  = remote.mode;
      s_raw_steering = remote.steering;

      if (current_speed > CONTROL_SPEED_MAX_LEVEL)  current_speed = CONTROL_SPEED_MAX_LEVEL;
      if (current_speed < -CONTROL_SPEED_MAX_LEVEL) current_speed = -CONTROL_SPEED_MAX_LEVEL;

      int16_t target_angle = (int16_t)(-(int32_t)remote.steering * 90 / 1000);
      if (target_angle < SERVO_ANGLE_MIN) target_angle = SERVO_ANGLE_MIN;
      if (target_angle > SERVO_ANGLE_MAX) target_angle = SERVO_ANGLE_MAX;
      Servo_SetSmoothAngle(target_angle, RAMP_REMOTE_STEP);
    }
    else if (!remote_active)
    {
      // 本地按键（PA11 前进 / PA12 后退，内部下拉，按下=1）
      uint8_t btn_forward  = HAL_GPIO_ReadPin(BTN_FWD_GPIO_Port, BTN_FWD_Pin);
      uint8_t btn_backward = HAL_GPIO_ReadPin(BTN_BACK_GPIO_Port, BTN_BACK_Pin);

      int8_t btn_cmd;
      if      (btn_forward == 1 && btn_backward == 0) { current_speed =  Runtime_Speed(); btn_cmd = 1; }
      else if (btn_backward == 1 && btn_forward == 0) { current_speed = -(int16_t)Runtime_Speed(); btn_cmd = -1; }
      else                                            { current_speed = 0; btn_cmd = 0; }
      operator_speed = current_speed;
      operator_update = 1;

      if (btn_cmd != last_btn_cmd)
      {
        last_btn_cmd = btn_cmd;
        if (btn_cmd == 1)       LOG("[BTN] FWD -> speed=%d", (int)Runtime_Speed());
        else if (btn_cmd == -1) LOG("[BTN] BACK -> speed=%d", -(int)Runtime_Speed());
        else                    LOG("[BTN] released -> STOP");
      }
    }

    // ===== 1.3 遥控避障锁（仅遥控模式；循迹模式由 patrol.c 自己的停障逻辑负责）=====
    /* 距离融合：VL53(mm) 与超声波(cm) 取【更近的有效值】——两者视场互补，
       任一发现近障都应停车，宁可保守。无效值(0/超量程)不参与比较。 */
    if (current_mode == MODE_MANUAL)
    {
      uint16_t vl53   = g_vl53_mm;
      uint32_t hc_cm  = HC_GetDistance_cm();
      uint16_t near_mm = 0xFFFFU;                     /* 0xFFFF = 前方净空 */
      /* ★ 优先信任激光：VL53 在量程内就只看它，不让超声波的假回波参与判定。
         只有 VL53 超量程（前方 1.2m 内确实没东西）时才回退到超声波兜底。 */
      if (vl53 != VL53_OUT_OF_RANGE && vl53 > 0U)
        near_mm = vl53;
      else if (hc_cm > 0U)
        near_mm = (uint16_t)(hc_cm * 10U);

      uint32_t now_ms = HAL_GetTick();

      /* (1) 进入锁定：需连续 OBS_CONFIRM_N 次判近，单次毛刺不触发 */
      if (near_mm <= OBS_LOCK_ON_MM)
      {
        if (s_obs_near_cnt < 0xFFU) s_obs_near_cnt++;
        if (!s_obs_lock && s_obs_near_cnt >= OBS_CONFIRM_N)
        {
          s_obs_lock = 1;
          s_obs_unlock_cnt = 0;
          /* LOG 走 115200 裸串口，只用 ASCII —— 中文会乱码成 "3?????????" */
          LOG("[OBS] LOCK on: front=%umm (<=%umm, confirmed x%u) -> forward blocked",
              near_mm, (unsigned)OBS_LOCK_ON_MM, (unsigned)s_obs_near_cnt);
        }
        if (s_obs_lock) s_obs_unlock_cnt = 0;         /* 障碍还在，任何确认都作废 */
      }
      else
      {
        s_obs_near_cnt = 0;                           /* 一旦读到不近就清确认计数 */
      }

      /* (2) 前进意图边沿检测：speed 从 <=0 跳到 >0 记一次 */
      if (s_obs_lock)
      {
        if (operator_update && s_obs_prev_cmd_spd <= 0 && operator_speed > 0)
        {
          /* 超时窗口：两次确认间隔过久则重新计数，避免"很久以前推过一次"被算进来 */
          if (s_obs_last_intent_ms != 0U &&
              (now_ms - s_obs_last_intent_ms) > OBS_UNLOCK_WINDOW_MS)
            s_obs_unlock_cnt = 0;
          s_obs_last_intent_ms = now_ms;

          /* 只有障碍已退到迟滞阈值之外，确认才计数——贴着障碍推摇杆不算数 */
          if (near_mm > OBS_LOCK_OFF_MM)
          {
            s_obs_unlock_cnt++;
            LOG("[OBS] unlock intent %u/%u (front=%umm)",
                s_obs_unlock_cnt, (unsigned)OBS_UNLOCK_NEED, near_mm);
            if (s_obs_unlock_cnt >= OBS_UNLOCK_NEED)
            {
              s_obs_lock = 0;
              s_obs_unlock_cnt = 0;
              LOG("[OBS] LOCK released by operator confirm");
            }
          }
          else
          {
            /* 限流：贴着障碍持续推摇杆时这条会每 17ms 打一次，几秒就刷屏几十条，
               把 [DIST]/[PIDTRK] 等真正有用的信息冲掉。每 500ms 最多打一条。 */
            static uint32_t s_lastRejLogMs = 0;
            if ((now_ms - s_lastRejLogMs) > 500U)
            {
              s_lastRejLogMs = now_ms;
              LOG("[OBS] unlock rejected: obstacle still near (front=%umm, need >%umm)",
                  near_mm, (unsigned)OBS_LOCK_OFF_MM);
            }
          }
        }
      }
      /* A safety-generated zero is not an operator release. Only received
         commands / physical buttons may create another unlock edge. */
      if (operator_update) s_obs_prev_cmd_spd = operator_speed;

      /* (3) 锁定生效：前进归零，后退放行（倒车脱困） */
      if (s_obs_lock && current_speed > 0)
        current_speed = 0;
    }
    else
    {
      /* 切出遥控模式：清锁，避免残留状态影响下次进遥控 */
      s_obs_lock = 0;
      s_obs_near_cnt = 0;
      s_obs_unlock_cnt = 0;
      s_obs_prev_cmd_spd = 0;
    }
    g_obs_lock = s_obs_lock;      /* 发布给 EnvTask 打 ENV_FLAG_OBS_LOCK 上报 */

    // ===== 1.4 龙芯下发的巡检命令（CAN 0x301 sub=0x01/0x02）=====
    if (g_patrol_cmd_ready)
    {
      uint8_t c = g_patrol_cmd_rx; g_patrol_cmd_ready = 0;
      switch (c) {
        case 0: Patrol_Stop();   LOG("[PATROL] cmd STOP");   break;
        case 1: Patrol_Start();  LOG("[PATROL] cmd START");  break;
        case 2: Patrol_Pause();  LOG("[PATROL] cmd PAUSE");  break;
        case 3: Patrol_Resume(); LOG("[PATROL] cmd RESUME"); break;
        default: break;
      }
    }
    if (g_patrol_act_ready)
    {
      uint8_t act = g_patrol_act_action; g_patrol_act_ready = 0;
      Patrol_ResumeFromPoint(act);       /* 到点放行：龙芯认完点给出下一步动作 */
      LOG("[PATROL] act point=%u action=%u", g_patrol_act_point, act);
    }

    // ===== 1.5 循迹模式：本地循线快环覆盖遥控值 =====
    /* 三模式（protocol.h）：
     *   MODE_REMOTE(0)      —— 不介入，用上面遥控消费得到的 speed/steering
     *   MODE_LINE_ONLY(1)   —— F4 本地 TCRT 循线
     *   MODE_LINE_VISION(3) —— 同样本地循线（保证断网可跑），龙芯视觉只作叠加约束
     * ★ 循线快环完全在 F4 本地闭合：即使 CAN/龙芯抖动或断开，巡线照常，
     *   不会因为链路问题冲出线外。龙芯只负责启停、认点、到点放行。 */
    if (current_mode == MODE_LINE_ONLY || current_mode == MODE_LINE_VISION)
    {
      if (previousMode != current_mode && !Patrol_IsActive()) Patrol_Start();     /* 切入循迹模式即自动启动 */

      int16_t p_spd = 0, p_str = 0;
      /* 前向距离：超声波(已中值滤波)，HC_NO_TARGET_CM 表示空旷 */
      uint16_t front = (uint16_t)HC_GetDistance_cm();
      if (front == 0u) front = HC_NO_TARGET_CM;

      PatrolEventT ev = Patrol_Update(&p_spd, &p_str, front);

      /* 台架联调开关(PATROL_BENCH_STEER_ONLY)：1=驱动轮不转、只动舵机。
         供电已拆分后默认恢复实车循迹；若需要悬空只验证转向，可临时改回 1。 */
#ifndef PATROL_BENCH_STEER_ONLY
#define PATROL_BENCH_STEER_ONLY 0
#endif
#if PATROL_BENCH_STEER_ONLY
      p_spd = 0;
#endif

      current_speed  = p_spd;
      s_raw_steering = p_str;

      /* 交给既有舵机管线（阿克曼：转向只由舵机执行） */
      int16_t ta = (int16_t)(-(int32_t)p_str * 90 / 1000);
      if (ta < SERVO_ANGLE_MIN) ta = SERVO_ANGLE_MIN;
      if (ta > SERVO_ANGLE_MAX) ta = SERVO_ANGLE_MAX;
      Servo_SetSmoothAngle(ta, RAMP_REMOTE_STEP);

      /* 事件上报龙芯（CAN 0x481 sub=0x01），由 TelemetryTask 取走 */
      if (ev != PATROL_EV_NONE) {
        g_patrol_event     = (uint8_t)ev;
        g_patrol_point_seq = Patrol_GetPointSeq();
        g_patrol_evt_ready = 1;
        LOG("[PATROL] event=%u seq=%u state=%u", ev, g_patrol_point_seq, Patrol_GetState());
      }
      g_patrol_state = (uint8_t)Patrol_GetState();
    }
    else if (Patrol_IsActive())
    {
      Patrol_Stop();                              /* 切出循迹模式即停止 */
      g_patrol_state = (uint8_t)Patrol_GetState();
      LOG("[PATROL] stopped (mode=%u)", current_mode);
    }

    previousMode = current_mode;
    // ===== 2. 阿克曼驱动速度合成 =====
    /* ★ 2026-07-21 阿克曼修正（实施方案 §2.6 / §3.1）：
     *   旧实现按【差速车】用 steering 合成 turn_factor，让左右轮一加一减。
     *   但本车是【阿克曼底盘】——转向完全由前轮舵机(PA0/TIM2_CH1)执行，
     *   驱动轮只负责推进。再叠加差速等于把同一个转向意图【施加两次】，
     *   会造成：转弯半径比舵机指令更小、内外轮与转向角不匹配而拖胎、
     *   直行时任何微小 steering 都让两轮速度不等而跑偏。
     *
     *   正解：两个驱动轮给【同一目标速度】，转向只由舵机负责。
     *   （严格阿克曼下内外轮应有微小速差 v_in/v_out = 1 ∓ (W/2)·tanδ/L，
     *     但本车轮距 W 小、巡检转弯半径大，该差值 <2%，且后轮多为差速器/
     *     独立驱动可自行吸收；引入它反而需要精确的 δ 反馈，得不偿失。
     *     故统一给同速——这也是绝大多数阿克曼小车的标准做法。） */
    #define CLAMP_SPD(v)  do { if ((v) > CONTROL_SPEED_MAX_LEVEL) (v) = CONTROL_SPEED_MAX_LEVEL; \
                                if ((v) < -CONTROL_SPEED_MAX_LEVEL) (v) = -CONTROL_SPEED_MAX_LEVEL; } while(0)

    int16_t left_speed  = current_speed;
    int16_t right_speed = current_speed;

    const uint8_t autonomous_mode =
        (current_mode == MODE_LINE_ONLY || current_mode == MODE_LINE_VISION) ? 1U : 0U;

    if (autonomous_mode)
    {
      /* 自主巡检快环属于 F4 本地控制，不受上位机遥控帧年龄影响。
         CAN 短暂断流时仍持续循线；模式/急停命令恢复后会立即接管。 */
      CLAMP_SPD(left_speed);
      CLAMP_SPD(right_speed);
      s_last_left_spd  = left_speed;
      s_last_right_spd = right_speed;
    }
    else if (!remote_active)
    {
      s_last_left_spd = current_speed;
      s_last_right_spd = current_speed;
    }
    else if ((uint32_t)(osKernelGetTickCount()-s_remote_tick) <= HB_ACTIVE_MAX)
    {
      /* 阿克曼：两驱动轮同速，不做差速合成（s_raw_steering 只驱动舵机，见第 1 段） */
      CLAMP_SPD(left_speed);
      CLAMP_SPD(right_speed);
      s_last_left_spd  = left_speed;
      s_last_right_spd = right_speed;
    }
    else if ((uint32_t)(osKernelGetTickCount()-s_remote_tick) <= HB_HOLD_MAX)
    {
      left_speed  = s_last_left_spd;
      right_speed = s_last_right_spd;
    }
    else
    {
      left_speed  = 0;
      right_speed = 0;
      current_speed = 0;
      remote_active = 0;
      s_last_left_spd  = 0;
      s_last_right_spd = 0;
      s_raw_steering   = 0;
      Servo_SetSmoothAngle(SERVO_ANGLE_MID, RAMP_SWITCH_STEP);

    }

    /* Every motion source shares this limit, including heartbeat-held commands.
       PID duty is still free to reach the limited encoder target under load. */
    left_speed = Control_Clamp(left_speed, Runtime_Speed());
    right_speed = Control_Clamp(right_speed, Runtime_Speed());
    /* DWT runs during IRQ masking and measures the actual encoder interval.
       Calibration no longer assumes every loop physically lasts exactly 17ms. */
    uint32_t cycles = DWT->CYCCNT;
    uint32_t elapsedUs = sampleCycles ? (uint32_t)(cycles-sampleCycles)/(SystemCoreClock/1000000U) : 17000U;
    sampleCycles = cycles;
    Encoder_UpdateElapsed(elapsedUs);
    int16_t outputs[2];
    /* 2026-10-09 single-wheel test: Motor1 drives ENC2; Motor2 drives ENC1. */
    Motion_Update(&motion,left_speed,s_raw_steering,Encoder2_GetDelta(),Encoder1_GetDelta(),
                  elapsedUs,Encoder_IsSampleValid(),outputs);
    /* High gear -> sharp turn: slow first, then progressively admit the
       requested angle. Servo_RampTick above consumes this bounded target
       on the next cycle; every motion source uses the same envelope. */
    int16_t safeSteering=Motion_LimitSteering(&motion,s_raw_steering);
    int16_t safeAngle=-(int16_t)((int32_t)safeSteering*90/1000);
    if(safeAngle<SERVO_ANGLE_MIN) safeAngle=SERVO_ANGLE_MIN;
    if(safeAngle>SERVO_ANGLE_MAX) safeAngle=SERVO_ANGLE_MAX;
    Servo_SetSmoothAngle(safeAngle,RAMP_REMOTE_STEP);
    Motor1_Set(outputs[0]);Motor2_Set(outputs[1]);
    g_pt_flags = (uint8_t)(1U | (motion.fault ? 4U : 0U));
    g_motion_fault = motion.fault;
    g_motion_dt_us = elapsedUs;
    g_pt_targL = g_pt_targR = (int16_t)motion.command;
    g_pt_measL = Motion_TelemetryCps(motion.measured[0]);g_pt_measR = Motion_TelemetryCps(motion.measured[1]);
    g_pt_outL = outputs[0];g_pt_outR = outputs[1];
    g_mot_speed = motion.fault ? 0 : (int16_t)motion.command;
    g_mot_steer_tele = -(int16_t)((int32_t)Servo_GetCurrentAngle() * 1000 / 90);
    g_mot_mode       = current_mode;

    g_remote_active = remote_active;

    controlDeadline += 17U;
    if ((int32_t)(controlDeadline-osKernelGetTickCount()) > 0) osDelayUntil(controlDeadline);
    else { controlDeadline=osKernelGetTickCount(); osDelay(1); }
  }
  /* USER CODE END StartMotionControlTask */
}

void StartScanTask(void *argument)
{
  /* USER CODE BEGIN StartScanTask */
  /* 云台状态：
       ① 默认上电居中静止，HC 前视，不自动跑极限位置；
       ② BOOT_PAN_SCAN_ENABLED 仅供台架显式启用全行程自检；
       ③ ON_DEMAND：激光近障触发的按需扫描——随运动状态机接入（后续里程碑）。
     HC/编码器/OLED 均已移出本任务（HC→RangingTask，编码器→MotionControl，OLED 移除）。 */
  LOG("[TASK] ScanTask: %s", BOOT_PAN_SCAN_ENABLED ?
      "bench boot sweep enabled" : "center hold; automatic boot sweep disabled");

  uint16_t pulse = BOOT_PAN_SCAN_ENABLED ? SERVO2_MIN : SERVO2_MID;
  int8_t   phase = BOOT_PAN_SCAN_ENABLED ? 0 : 2; /* 0=去MAX 1=回MIN 2=居中 */
  Servo2_SetPulse(pulse);
  osDelay(300);                 /* 等云台到位 */

  for(;;)
  {
    WDG_Kick(WDG_TASK_SCAN);   /* 只打存活点，实际喂狗由 MotionControlTask 聚合判定 */

    if (phase == 0)
    {
      pulse += SWEEP2_STEP;
      if (pulse >= SERVO2_MAX) { pulse = SERVO2_MAX; phase = 1; }
      Servo2_SetPulse(pulse);
      osDelay(10);
    }
    else if (phase == 1)
    {
      pulse -= SWEEP2_STEP;
      if (pulse <= SERVO2_MID) { pulse = SERVO2_MID; phase = 2;
        LOG("[SCAN] boot sweep done -> center hold (dist=%lucm)", HC_GetDistance_cm()); }
      Servo2_SetPulse(pulse);
      osDelay(10);
    }
    else
    {
      /* 居中静止：低频保持（后续 ON_DEMAND 扫描在此接收触发） */
      Servo2_SetPulse(SERVO2_MID);
      osDelay(100);
    }
  }
  /* USER CODE END StartScanTask */
}

void Ranging(void *argument)
{
  /* USER CODE BEGIN Ranging */
  /* 高频测距采集（AboveNormal1，1ms 粒度）——《深度优化报告》M1/M3：
       · HC-SR04 状态机 1ms 推进（旧版在 ScanTask 10ms 粒度 + OLED 阻塞，触发
         时序被拖慢；现在 TRIG 10us/50us 相位仅耗 1~2ms，测距可达物理极限）；
       · VL53L0X 每 10ms 非阻塞读一次（连续测距模式，仅查就绪位，绝不忙等）。
     全程无打印、无 OLED、无阻塞大户——它只做采集和发布。 */
  LOG("[TASK] RangingTask: HC @1ms tick + VL53 try-read @10ms");

  uint32_t cyc = 0;
  uint32_t hc_last_ms = 0;   /* 上次发起 HC 测量的时刻，用于 ≥60ms 间隔限速 */
  uint32_t vl53_retry_ms = HAL_GetTick();
  /* VL53 超量程去抖：连续 VL53_MISS_N 次才判"真的没目标"，期间保持最后有效值 */
  #define VL53_MISS_N   5U   /* 5 次 × 10ms ≈ 50ms */
  uint8_t  s_vl53_miss = 0;
  for(;;)
  {
    WDG_Kick(WDG_TASK_RANGING);
    /* HC 状态机推进（触发时序 + 超时判定；边沿在 TIM2 中断捕获） */
    HC_ProcessTick();
    /* ★ HC-SR04 测量间隔 ≥60ms(HC_MEAS_INTERVAL_MS)：数据手册要求相邻测量≥60ms，
       否则上一次 ping 余响未散就再发，近距目标(<50cm)"回波时有时无"(pulse 在 0 与
       真值间跳)——这正是近距 [DIST] 间歇 0 的根因。原 back-to-back(~150-300Hz)过快。 */
    if (!HC_IsMeasuring() && (HAL_GetTick() - hc_last_ms >= HC_MEAS_INTERVAL_MS))
    {
      HC_StartMeasurement();
      hc_last_ms = HAL_GetTick();
    }

    /* 循迹 TCRT×3：内部固定5ms中值/迟滞采样，多任务读取不会加快去抖。 */
    g_line_bits = LineTrack_PackBits(LineTrack_Read());
    Runtime_SetLineReady(LineTrack_IsCalibrated());

    /* VL53 非阻塞取样（~30ms 测量预算，10ms 轮询足够取走每个样本） */
    if ((++cyc % 10U) == 0U)
    {
      uint16_t mm;
      if (VL53_TryReadRange_mm(&mm))
      {
        if (mm != VL53_OUT_OF_RANGE)
        {
          /* 有效读数：立即发布并清失效计数 */
          g_vl53_mm = mm;
          s_vl53_miss = 0;
          g_vl53_ok_cnt++;
        }
        else
        {
          /* ★ 2026-07-23 超量程去抖：
             VL53L0X 在目标接近量程上限(~1.2m)或反射率低时，会【间歇】返回超量程
             哨兵 8190。实测约 1/3 的采样是 8190，而 g_vl53_ok_cnt 同期稳定增长
             （每秒 20~25 次有效读数）—— 说明传感器工作正常，只是边缘条件下不稳。
             旧实现把 8190 直接覆盖 g_vl53_mm，导致上位机与小屏看到的是
             "880mm / 无数据" 来回跳，也就是"拿不到稳定数据"。
             现改为：连续 VL53_MISS_N 次超量程才真的对外发布 8190，
             期间保持最后一个有效值。与 DHT11 的 s_dht_fail>=3 去抖同一思路。 */
          if (s_vl53_miss < 0xFFU) s_vl53_miss++;
          if (s_vl53_miss >= VL53_MISS_N) g_vl53_mm = VL53_OUT_OF_RANGE;
        }
      }
    }

    /* VL53 运行时自恢复：未就绪时每 ~2s 重试一次 init。上电后再补接线/补供电也能
       自动恢复，无需重烧。仅传感器缺失时才跑（正常工作此分支从不触发，零开销）。 */
    if (!VL53_IsPresent()) g_vl53_mm = VL53_OUT_OF_RANGE;
    if (!VL53_IsPresent() && HAL_GetTick() - vl53_retry_ms >= 2000U)
    {
      /* ★ 2026-07-23：与 MLX 同理，先做总线级恢复。VL53L0X 挂死拉低 SDA 时，
         单纯重跑 VL53_Init 会在第一条 I2C 命令上就失败，永远恢复不了。
         每 4s 才做一次总线恢复（隔次），避免正常缺件时频繁扰动总线。 */
      static uint8_t s_vl53RecoverToggle = 0;
      if (s_vl53RecoverToggle ^= 1U) {
        uint8_t busOk = I2C2_BusRecover();
        if (!busOk) LOG("[VL53] I2C2 bus recover: SDA STILL LOW (check 3V3 supply / pull-ups)");
      }
      if (VL53_Init() == 0) LOG("[VL53] runtime recovery OK -> ranging live");
      vl53_retry_ms = HAL_GetTick();
    }

    osDelay(1);
  }
  /* USER CODE END Ranging */
}

void Telemetry(void *argument)
{
  /* USER CODE BEGIN Telemetry */
  /* 上报专职任务（Normal，20ms 基准节拍）——把串口 TX 从运动环剥离：
       · ~60ms：7B 遥测帧 + 0x5A 扩展帧（距离/编码器）
       · PID 遥测 0x62：测试进行中 20ms(50Hz) 高频；平时 200ms 低频
     所有 TX 走 USART3 互斥锁，与 EnvTask 的 0x5C 串行化。 */
  LOG("[TASK] TelemetryTask: tele@60ms + PID tele 50Hz(test)/5Hz(idle)");

  uint8_t  frame[FRAME_PIDTELE_LENGTH];   /* 27B，够放所有帧型 */
  uint8_t  exFrame[FRAME_EXT_LENGTH];
  ControlData cd;
  #if PID_TUNING_ENABLED
  uint16_t seq = 0;
  #endif
  uint32_t tick = 0;

  for(;;)
  {
    WDG_Kick(WDG_TASK_TELEMETRY);
    /* ★遥测与命令心跳解耦（2026-07-10）：传感器数据【无条件】持续上报，
       绝不因命令链路 ~510ms 无帧(g_remote_active=0)而停发。
       —— 这是"掉线后界面数据被冻结"的根治：命令链路的任何抖动(EMI/偶发丢帧/
          上位机卡顿)都不再导致上行数据黑屏；心跳只用于运动安全停车
          (见 MotionControlTask 的 HB_HOLD_MAX 分支)，不再门控上行数据。 */
    {
      tick++;
      if (tick % 25U == 0U) {
        uint8_t status[20] = {0xAA, 0x64, 16};
        Runtime_Status(&status[3]);
        status[19] = Protocol_CalculateChecksum(status,19);
        USART3_SendFrameSync(status,20);
#if LINK_USE_CAN
        CANLink_Send(COBID_EVT,&status[3],8);
        CANLink_Send(COBID_EVT,&status[11],8);
#endif
      }

      if (tick % 150U == 0U) {
        LOG("[MOTION] target=%d cps | motor1/left=%d cps pwm=%d | motor2/right=%d cps pwm=%d | dt=%luus fault=%u",
          g_mot_speed,g_pt_measL,g_pt_outL,g_pt_measR,g_pt_outR,(unsigned long)g_motion_dt_us,g_motion_fault);
      }
#if LINK_USE_CAN
      if (tick % 5U == 0U) {
        uint8_t motionStatus[8]={6,(uint8_t)(g_mot_speed>>8),(uint8_t)g_mot_speed,
          (uint8_t)(g_pt_measR>>8),(uint8_t)g_pt_measR,(uint8_t)(g_pt_measL>>8),(uint8_t)g_pt_measL,g_motion_fault};
        uint8_t motionOutput[8]={7,(uint8_t)(g_pt_outR>>8),(uint8_t)g_pt_outR,
          (uint8_t)(g_pt_outL>>8),(uint8_t)g_pt_outL,(uint8_t)(g_motion_dt_us/1000U),g_motion_fault,1};
        CANLink_Send(COBID_EVT,motionStatus,8);CANLink_Send(COBID_EVT,motionOutput,8);
      }
#endif
      /* ---- 7B 遥测 + 扩展帧（每 3 拍 = 60ms） ---- */
      if (tick % 3U == 0U)
      {
        cd.speed    = g_mot_speed;
        cd.steering = g_mot_steer_tele;
        cd.mode     = g_mot_mode;
        Protocol_PackFrame(&cd, frame);
        USART3_SendFrameSync(frame, FRAME_LENGTH);

        uint16_t dist_cm = (uint16_t)HC_GetDistance_cm();
        uint8_t exLen = Protocol_PackTelemetryEx(
            g_mot_speed, g_mot_steer_tele, g_mot_mode,
            dist_cm, Encoder1_GetCount(), Encoder2_GetCount(), exFrame);
        USART3_SendFrameSync(exFrame, exLen);

#if LINK_USE_CAN
        /* CAN 上行（非阻塞，无锁）：0x181 核心遥测 + 0x281 编码器。
           大端定点，各 ≤8B（实施方案 §3.5.1）。
           ★ dist 用 HC_NO_TARGET_CM(0xFFFF) 哨兵表示"无目标/超量程"，与真实近距
             0cm 彻底区分——避免消费端把"前方空旷"误读成"贴脸 0cm 障碍"。 */
        uint16_t can_dist = (dist_cm == 0u) ? HC_NO_TARGET_CM : dist_cm;
        CANLink_SendTeleCore(g_mot_speed, g_mot_steer_tele, g_mot_mode, can_dist, g_line_bits);
        CANLink_SendTeleEnc(Encoder1_GetCount(), Encoder2_GetCount());
#endif
      }

#if LINK_USE_CAN
      /* ---- 0x701 节点心跳 @1Hz（每 50 拍 = 1s）：供龙芯判 F4 存活 ---- */
      CANLink_Service();
      if (tick % 50U == 0U)
      {
        CANLink_SendHeartbeat(CAN_NODE_STATE_OPERATIONAL);
      }

      /* ---- 巡检事件 0x481 sub=0x01：事件驱动，产生即发（到点/丢线/受阻）---- */
      if (g_patrol_evt_ready)
      {
        uint8_t ev = g_patrol_event, sq = g_patrol_point_seq, st = g_patrol_state;
        g_patrol_evt_ready = 0;
        CANLink_SendPatrolEvent(ev, sq, st);
      }

#if CAN_LOOPBACK_TEST
      /* ★ P1 自环自证：每 3 拍(60ms) 自发自收一帧 0x301 → 看 [CAN] 的 rxoth 涨不涨。
         静默自环下 CANTX 保持隐性，不碰外部总线，也不需要 ACK。 */
      if (tick % 3U == 0U)
      {
        CANLink_LoopbackSelfTest();
      }
#endif
#endif

      /* ---- PID 遥测 0x62：测试中每拍(20ms=50Hz)，平时每 10 拍(200ms) ---- */
      #if PID_TUNING_ENABLED
      uint8_t testActive = (g_pt_flags & 0x02U) != 0U;
      if (testActive || (tick % 10U == 0U))
      {
        uint8_t len = Protocol_PackPidTele(
            seq++, g_pt_flags,
            g_pt_targL, g_pt_measL, g_pt_outL,
            g_pt_targR, g_pt_measR, g_pt_outR,
            Encoder1_GetCount(), Encoder2_GetCount(), frame);
        USART3_SendFrameSync(frame, len);
#if LINK_USE_CAN
        CANLink_SendPidTele((uint16_t)(seq - 1U), g_pt_flags,
            g_pt_targL, g_pt_measL, g_pt_outL,
            g_pt_targR, g_pt_measR, g_pt_outR,
            Encoder1_GetCount(), Encoder2_GetCount());
#endif
      }
      #endif
    }
    osDelay(20);
  }
  /* USER CODE END Telemetry */
}

void Env(void *argument)
{
  /* USER CODE BEGIN Env */
  /* 慢速环境/安全任务（BelowNormal，100ms）：MQ2/火焰/DHT11/蜂鸣 + 0x5C 上报。
     VL53 已迁 RangingTask（本任务读 g_vl53_mm 快照）——DHT11 阻塞读(4~25ms)
     不再拖累激光采样（修复《深度优化报告》问题 P3）。 */

  static int8_t  s_temp   = 0;
  static uint8_t s_humi   = 0;
  static uint8_t s_dht_ok = 0;
  static uint8_t s_ambient_hot = 0;
  static uint8_t s_dht_fail = 0;   /* 连续失败计数：去抖，偶发失败不丢显示 */
  /* ★ 2026-07-23：最后一次成功读取的时刻。
     原来只有"连续失败 3 次"这一个判据，但如果失败与成功交替出现
     （偶发成功把 s_dht_fail 清零），就永远达不到 3 次，
     即使实际刷新率已经低到几十秒一次，上位机看到的仍是 dhtOk=1 的陈旧值。
     加一个绝对新鲜度判据：超过 DHT_STALE_MS 没有成功读到，一律判无效。 */
  #define DHT_SAMPLE_MS   2100U    /* DHT11 不允许快速重读，留出略大于 2s 的裕量 */
  #define DHT_STALE_MS    7000U    /* 连续约 3 个采样周期无成功就明确标无效 */
  static uint32_t s_dht_ok_ms = 0;
  static uint16_t s_dht_seq = 0;
  static uint32_t s_dht_next_ms = 0;

  /* 障碍双重验证阈值：VL53(mm) 与 超声波(cm) 同时近才确认 */
  #define ENV_OBST_TH_MM   300U   /* 30cm */
  #define ENV_OBST_TH_CM    30U

  uint32_t cycle = 0;

  /* DHT11 上电需 ~1s 稳定 */
  osDelay(1000);

  for (;;)
  {
    WDG_Kick(WDG_TASK_ENV);
    /* ---- 1. 采集（10Hz；激光值来自 RangingTask 快照） ---- */
    Flame_Tick();
    uint16_t gas_raw   = MQ2_ReadRaw();
    uint8_t  gas_alarm = MQ2_IsAlarm();
    uint8_t  flame     = Flame_IsDetected();

    uint16_t vl53_mm = g_vl53_mm;                    /* RangingTask 发布 */
    uint8_t  vl53_ok = (vl53_mm != VL53_OUT_OF_RANGE);

    /* ---- DHT11：严格按 >=2s 单次采样。旧版失败后每 30ms 连读三次，传感器
       尚未完成内部测量就再次收到起始脉冲，既不能提高成功率，还连续占用实时任务。 */
    uint32_t nowMs = HAL_GetTick();
    if (s_dht_next_ms == 0U || (int32_t)(nowMs - s_dht_next_ms) >= 0)
    {
      int8_t  t = s_temp;
      uint8_t h = s_humi;
      uint8_t ok = DHT11_Read(&t, &h);
      s_dht_next_ms = HAL_GetTick() + DHT_SAMPLE_MS;
      if (ok)
      {
        s_temp = t; s_humi = h;     /* 更新最后有效值 */
        s_dht_fail = 0;
        s_dht_ok = 1;
        s_dht_ok_ms = HAL_GetTick();
        if (++s_dht_seq == 0) ++s_dht_seq;
      }
      else
      {
        /* 单次失败不立刻判无效：保持上次值继续显示（DHT11 偶发失败很常见）。
           连续 3 次(≈6s)都失败才判传感器真失效 → 上位机才显示"--"。 */
        if (s_dht_fail < 250U) s_dht_fail++;
        if (s_dht_fail >= 3U) s_dht_ok = 0;
      }
      /* 绝对新鲜度兜底：成功/失败交替时 s_dht_fail 会被反复清零而永远到不了 3，
         此时上位机会一直看到 dhtOk=1 的陈旧值。超过 DHT_STALE_MS 无成功即判无效。 */
      if (s_dht_ok_ms != 0U && (HAL_GetTick() - s_dht_ok_ms) > DHT_STALE_MS)
        s_dht_ok = 0;
    }

    /* ---- 2. 障碍双重验证 ---- */
    uint16_t hc_cm = (uint16_t)HC_GetDistance_cm();
    uint8_t obstacle = (vl53_ok  && vl53_mm < ENV_OBST_TH_MM) &&
                       (hc_cm != 0U && hc_cm < ENV_OBST_TH_CM);

    /* ---- 3. 报警等级 + 蜂鸣 + PD2 联动 ---- */
    uint8_t       alarm;
    BuzzerPattern pat;
    uint32_t alarmNow=HAL_GetTick();
    uint8_t remoteFlags=Runtime_RemoteFlags(alarmNow);
    uint8_t remoteVisionAlarm=(remoteFlags&1U)?2U:(remoteFlags&2U)?1U:0U;
    uint8_t legacyVision=(g_remote_vision_ms && alarmNow-g_remote_vision_ms<3000U)?g_remote_vision_alarm:0U;
    if(legacyVision>remoteVisionAlarm) remoteVisionAlarm=legacyVision;
    if (s_dht_ok && HAL_GetTick()-s_dht_ok_ms<7000U) {
      if(s_temp>=45) s_ambient_hot=1;
      else if(s_temp<=42) s_ambient_hot=0;
    } else s_ambient_hot=0;
    if (s_ambient_hot || (remoteFlags&4U))           { alarm = ALARM_LV_FIRE; pat = BUZZER_FLAME; }
    else if (flame)                   { alarm = ALARM_LV_FIRE; pat = BUZZER_FLAME;    }
    else if (remoteVisionAlarm == 2U)
                                { alarm = ALARM_LV_FIRE; pat = BUZZER_FLAME;    }
    else if (gas_alarm)          { alarm = ALARM_LV_FIRE; pat = BUZZER_GAS;      }
    else if (remoteVisionAlarm == 1U)
                                { alarm = ALARM_LV_FIRE; pat = BUZZER_GAS;      }
    else if (obstacle)           { alarm = ALARM_LV_WARN; pat = BUZZER_OBSTACLE; }
    else                         { alarm = ALARM_LV_NONE; pat = BUZZER_OFF;      }

    Buzzer_SetPattern(pat);
    HAL_GPIO_WritePin(ALARM_OUT_GPIO_Port, ALARM_OUT_Pin,
                      (alarm == ALARM_LV_FIRE) ? GPIO_PIN_SET : GPIO_PIN_RESET);

    /* ---- 4. flags ---- */
    uint8_t flags = 0;
    if (gas_alarm)           flags |= ENV_FLAG_GAS;
    if (flame)               flags |= ENV_FLAG_FLAME;
    if (s_dht_ok)            flags |= ENV_FLAG_DHT_OK;
    if (vl53_ok)             flags |= ENV_FLAG_VL53_OK;
    if (VL53_IsPresent())    flags |= ENV_FLAG_VL53_PRESENT;   /* 在位≠有效：死值可辨 */
    if (obstacle)            flags |= ENV_FLAG_OBSTACLE;
    if (Buzzer_IsSounding()) flags |= ENV_FLAG_BUZZER;
    if (g_obs_lock)          flags |= ENV_FLAG_OBS_LOCK;   /* 遥控避障锁生效中 */

    Runtime_Env(flags,s_temp,s_dht_seq,s_dht_ok_ms);

    /* ---- 5. 5Hz 上报 0x5C（与命令心跳解耦：无条件持续上报，不掉线） ---- */
    if ((cycle % 2U) == 0U)
    {
      uint8_t envFrame[FRAME_ENV_LENGTH];
      uint8_t envLen = Protocol_PackEnvFrame(
          gas_raw, vl53_mm, s_temp, s_humi, flags, alarm, envFrame);
      USART3_SendFrameSync(envFrame, envLen);

#if LINK_USE_CAN
      /* CAN 上行 0x381 环境帧（大端定点 8B，实施方案 §3.5.1） */
      CANLink_SendEnv(gas_raw, vl53_mm, s_temp, s_humi, flags, alarm);
#endif
    }

    /* 诊断日志(~1s一次) */
    if ((cycle % 10U) == 0U)
    {
      LOG("[DIST] ultra(HC)=%ucm pulse=%uus | laser(VL53)=%umm ok=%u okcnt=%lu | remote=%u",
          hc_cm, (unsigned)HC_GetLastPulse_us(), vl53_mm, vl53_ok,
          g_vl53_ok_cnt, g_remote_active);
      LOG("[ENV]  gas=%u T=%dC H=%u%% dhtOk=%u fail=%u err=%u flame=%u obst=%u",
          gas_raw, (int)s_temp, s_humi, s_dht_ok, s_dht_fail,
          (unsigned)DHT11_GetLastError(), flame, obstacle);
      /* 循迹核查：L/C/R=压线(1)/离线(0)，J=路口 X=丢线。压/离黑线时应即时翻转 */
      { uint8_t lb = g_line_bits;
        LOG("[LINE] L=%u C=%u R=%u  J=%u X=%u  (bits=0x%02X)",
            (lb & LINE_BIT_L) ? 1u : 0u, (lb & LINE_BIT_C) ? 1u : 0u,
            (lb & LINE_BIT_R) ? 1u : 0u, (lb & LINE_BIT_JUNCTION) ? 1u : 0u,
            (lb & LINE_BIT_LOST) ? 1u : 0u, lb); }
#if LINETRACK_USE_ADC
      /* ★ 阈值标定用：白底放一次、黑线放一次，各记三路读数，
         按 linetrack.h 里的说明定 LINE_ADC_ON_TH / OFF_TH。
         同时打 MQ2 通道，便于确认 DMA 扫描确实在刷新（四个值都不动=DMA 停了）。 */
      { uint16_t rl, rc, rr, off[3], on[3]; uint8_t ready;
        LineTrack_GetRaw(&rl, &rc, &rr);
        LineTrack_GetThresholds(off, on, &ready);
        LOG("[LINE_ADC] L=%4u(%u~%u) C=%4u(%u~%u) R=%4u(%u~%u) | mq2=%4u dma=%u ready=0x%02X",
            rl, (unsigned)off[0], (unsigned)on[0],
            rc, (unsigned)off[1], (unsigned)on[1],
            rr, (unsigned)off[2], (unsigned)on[2],
            (unsigned)g_adc_dma[ADC_CH_MQ2], ADC_IsStreaming(), ready); }
#endif
    }

    cycle++;
    osDelay(100);
  }
  /* USER CODE END Env */
}

void Thermal(void *argument)
{
  /* USER CODE BEGIN Thermal */
#if THERMAL_TASK_ENABLED
  /* 热成像原始帧转发（Low，~2Hz，USART1 专线）：F4 只读原始帧不解算，
     0x5E EEPROM(上电一次) + 0x5D 原始帧 → 龙芯 Melexis 解算。 */
  uint8_t initialized = 0;
  uint32_t retryAt = 0;
  uint8_t  frame[FRAME_MLXCHUNK_MAXLEN];
  uint8_t  eeSent = 0;
  uint32_t loopCnt = 0, framesSent = 0, txFail = 0;
  uint32_t nextEeMs = 0;
  uint16_t failStreak = 0;   /* 连续原始帧读取失败计数：坏态自恢复触发 */
  for (;;)
  {
    uint32_t now = HAL_GetTick();
    uint16_t reason = Runtime_ThermalReason(now);
    if (!reason) {
      Runtime_SetThermalState(TH_STOPPED);
      initialized = 0; eeSent = 0; nextEeMs = 0; failStreak = 0;
      osDelay(100); continue; /* no I2C reads, TX or computation while off */
    }
    if (!initialized) {
      if (retryAt && (int32_t)(now-retryAt)<0) { osDelay(100); continue; }
      Runtime_SetThermalState(TH_STARTING);
      if (Thermal_Init() != 0) {
        Runtime_SetThermalState(TH_FAULT); I2C3_BusRecover();
        retryAt = HAL_GetTick()+2000U; osDelay(100); continue;
      }
      initialized = 1; retryAt = 0; eeSent = 0; nextEeMs = 0;
      osDelay(600); /* first measurement after wake */
    }
    if (Runtime_TakeEepromRequest()) { eeSent=0; nextEeMs=0; }
    {
      if (!eeSent && (nextEeMs == 0U || (int32_t)(HAL_GetTick() - nextEeMs) >= 0))
      {
        const uint16_t *ee = Thermal_GetEE();
        uint8_t eeTxOk = 1;
        for (uint8_t idx = 0; (int)idx * MLX_CHUNK_WORDS < MLX_EE_WORDS; idx++)
        {
          int start = (int)idx * MLX_CHUNK_WORDS;
          int rem   = MLX_EE_WORDS - start;
          uint8_t cnt = (rem >= MLX_CHUNK_WORDS) ? MLX_CHUNK_WORDS : (uint8_t)rem;
          uint8_t len = Protocol_PackMlxChunk(FRAME_EEPROM_MARKER, idx, &ee[start], cnt, frame);
          /* EEPROM 决定所有温度解算参数，每块发两遍。龙芯按 idx 位图去重，
             任一副本通过校验即可，优先保证标定参数可靠到达。 */
          for (uint8_t copy = 0; copy < 2U; copy++) {
            if (HAL_UART_Transmit(&huart1, frame, len, 500) != HAL_OK) {
              eeTxOk = 0;
              txFail++;
            }
          }
        }
        if (eeTxOk) {
          eeSent = 1;
          nextEeMs = HAL_GetTick() + 10000U;
          LOG("[THERM] EEPROM forwarded hash=%08lX recover=%lu (2 copies/chunk)",
              (unsigned long)Thermal_GetEEFingerprint(),
              (unsigned long)Thermal_GetEERecoverCount());
        } else {
          nextEeMs = HAL_GetTick() + 1000U;
          LOG("[THERM] EEPROM TX failed, retry next loop (txFail=%lu)",
              (unsigned long)txFail);
        }
      }

      int rf = Thermal_ReadRawSubpage();
      if (rf == 0)
      {
        failStreak = 0;
        const uint16_t *raw = Thermal_GetRawFrame();
        uint8_t rawTxOk = 1;
        for (uint8_t idx = 0; (int)idx * MLX_CHUNK_WORDS < MLX_FRAME_WORDS; idx++)
        {
          int start = (int)idx * MLX_CHUNK_WORDS;
          int rem   = MLX_FRAME_WORDS - start;
          uint8_t cnt = (rem >= MLX_CHUNK_WORDS) ? MLX_CHUNK_WORDS : (uint8_t)rem;
          uint8_t len = Protocol_PackMlxChunk(FRAME_RAWTHERM_MARKER, idx, &raw[start], cnt, frame);
          if (HAL_UART_Transmit(&huart1, frame, len, 500) != HAL_OK) {
            rawTxOk = 0;
            txFail++;
            break;
          }
        }
        if (rawTxOk) { framesSent++; Runtime_SetThermalState(TH_STREAMING); }
        else Runtime_SetThermalState(TH_FAULT);
      }
      else
      {
        /* MLX 连续读失败=传感器掉坏态(供电/EMI/地弹后停刷)。就绪位轮询现已超时
           返回(见 MLX90640_API.c 修复)，不再永久挂死；此处连续 ~2s(10×200ms)
           失败即重初始化 MLX 恢复，USART1(PA9) 热成像输出可自愈，不需重启 F4。 */
        Runtime_SetThermalState(TH_FAULT);
        if (++failStreak >= 3U)
        {
          /* ★ 2026-07-23：先做【总线级】恢复再重初始化。
             MLX90640 在供电波动/EMI 下会在传输中途挂死并把 SDA 一直拉低，
             此时重发配置命令必然继续失败 —— 这正是日志里 "re-init FAILED"
             反复出现却永远好不了的原因（MLX90640_I2CInit() 本身还是空函数）。
             I2C3_BusRecover() 手动打 9 个 SCL 时钟逼从机释放 SDA，
             补 STOP 时序，再软复位并重初始化 I2C3 外设。 */
          uint8_t busOk = I2C3_BusRecover();
          LOG("[THERM] raw read fail x%u -> I2C3 bus recover(%s, cnt=%lu) + re-init",
              failStreak, busOk ? "SDA released" : "SDA STILL LOW",
              (unsigned long)I2C_RecoverCount());
          if (Thermal_Init() == 0) {
            /* 标定副本未变化，重初始化不抢占串口重复发 EEPROM；周期重发仍能
               覆盖龙芯晚启动。等待一个刷新周期后再读取，防止复位风暴。 */
            failStreak = 0; eeSent = 0; nextEeMs = 0;
            osDelay(600);
            LOG("[THERM] re-init OK, calibration retained");
          } else {
            failStreak = 0;
            osDelay(2000);
            LOG("[THERM] re-init FAILED, retry in 2s");
          }
        }
        else osDelay(50);
      }
      if ((++loopCnt % 10U) == 0U)
        LOG("[THERM] raw-forward remote=%u frames_sent=%lu txFail=%lu",
            g_remote_active, framesSent, txFail);
      /* 每 10s 重发双副本 EEPROM，龙芯晚启动/重启后最多等待 10s 即可恢复标定。 */
      if (eeSent && (int32_t)(HAL_GetTick() - nextEeMs) >= 0) eeSent = 0;
    }
    /* GetFrameData 内部等待 data-ready；这里只做最小让步，不再额外固定等待 200ms。 */
    osDelay(5);
  }
#else
  for (;;) { osDelay(1000); }
#endif
  /* USER CODE END Thermal */
}
